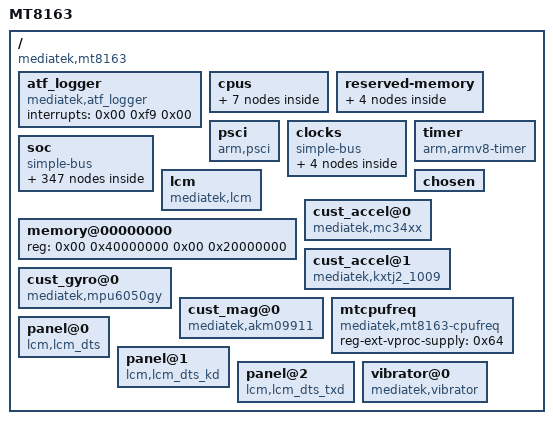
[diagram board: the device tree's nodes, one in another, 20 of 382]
/dts-v1/;

/ {
	model = "MT8163";
	compatible = "mediatek,mt8163";
	interrupt-parent = <0x01>;
	#address-cells = <0x02>;
	#size-cells = <0x02>;

	atf_logger {
		compatible = "mediatek,atf_logger";
		interrupts = <0x00 0xf9 0x00>;
	};

	cpus {
		#address-cells = <0x01>;
		#size-cells = <0x00>;

		cpu@0 {
			device_type = "cpu";
			compatible = "arm,cortex-a53";
			reg = <0x00>;
			enable-method = "mt-boot";
			cpu-idle-states = <0x02 0x02 0x03 0x03 0x03>;
			cpu-release-addr = <0x00 0x40000200>;
			clock-frequency = "M|m";
			linux,phandle = <0x07>;
			phandle = <0x07>;
		};

		cpu@1 {
			device_type = "cpu";
			compatible = "arm,cortex-a53";
			reg = <0x01>;
			enable-method = "mt-boot";
			cpu-idle-states = <0x02 0x02 0x03 0x03 0x03>;
			cpu-release-addr = <0x00 0x40000200>;
			clock-frequency = "M|m";
			linux,phandle = <0x08>;
			phandle = <0x08>;
		};

		cpu@2 {
			device_type = "cpu";
			compatible = "arm,cortex-a53";
			reg = <0x02>;
			enable-method = "mt-boot";
			cpu-idle-states = <0x02 0x02 0x03 0x03 0x03>;
			cpu-release-addr = <0x00 0x40000200>;
			clock-frequency = "M|m";
			linux,phandle = <0x09>;
			phandle = <0x09>;
		};

		cpu@3 {
			device_type = "cpu";
			compatible = "arm,cortex-a53";
			reg = <0x03>;
			enable-method = "mt-boot";
			cpu-idle-states = <0x02 0x02 0x03 0x03 0x03>;
			cpu-release-addr = <0x00 0x40000200>;
			clock-frequency = "M|m";
			linux,phandle = <0x0a>;
			phandle = <0x0a>;
		};

		idle-states {
			entry-method = "arm,psci";

			cpu-sleep-0-0 {
				compatible = "arm,idle-state";
				arm,psci-suspend-param = <0x10000>;
				entry-latency-us = <0x258>;
				exit-latency-us = <0x258>;
				min-residency-us = <0x4b0>;
				linux,phandle = <0x03>;
				phandle = <0x03>;
			};

			cluster-sleep-0 {
				compatible = "arm,idle-state";
				arm,psci-suspend-param = <0x2010000>;
				entry-latency-us = <0x320>;
				exit-latency-us = <0x3e8>;
				min-residency-us = <0x7d0>;
				linux,phandle = <0x02>;
				phandle = <0x02>;
			};
		};
	};

	reserved-memory {
		#address-cells = <0x02>;
		#size-cells = <0x02>;
		ranges;

		atf-reserved-memory@43000000 {
			compatible = "mediatek,mt8163-atf-reserved-memory";
			no-map;
			reg = <0x00 0x43000000 0x00 0x30000>;
		};

		ram_console-reserved-memory@44400000 {
			compatible = "mediatek,ram_console";
			reg = <0x00 0x44400000 0x00 0x10000>;
		};

		minirdump-reserved-memory@444f0000 {
			compatible = "mediatek,minirdump";
			reg = <0x00 0x444f0000 0x00 0x10000>;
		};

		consys-reserve-memory {
			compatible = "mediatek,consys-reserve-memory";
			no-map;
			size = <0x00 0x200000>;
			alignment = <0x00 0x200000>;
		};
	};

	psci {
		compatible = "arm,psci";
		method = "smc";
		cpu_suspend = <0x84000001>;
		cpu_off = <0x84000002>;
		cpu_on = <0x84000003>;
		affinity_info = <0x84000004>;
	};

	clocks {
		#address-cells = <0x02>;
		#size-cells = <0x02>;
		compatible = "simple-bus";
		ranges;

		clk_null {
			compatible = "fixed-clock";
			#clock-cells = <0x00>;
			clock-frequency = <0x00>;
			linux,phandle = <0x38>;
			phandle = <0x38>;
		};

		clk26m {
			compatible = "fixed-clock";
			#clock-cells = <0x00>;
			clock-frequency = <0x18cba80>;
			linux,phandle = <0x29>;
			phandle = <0x29>;
		};

		clk32k {
			compatible = "fixed-clock";
			#clock-cells = <0x00>;
			clock-frequency = <0x7d00>;
		};

		dummy26m {
			compatible = "fixed-clock";
			clock-frequency = <0x18cba80>;
			#clock-cells = <0x00>;
		};
	};

	timer {
		compatible = "arm,armv8-timer";
		interrupt-parent = <0x04>;
		interrupts = <0x01 0x0d 0xf08 0x01 0x0e 0xf08 0x01 0x0b 0xf08 0x01 0x0a 0xf08>;
		clock-frequency = <0xc65d40>;
	};

	soc {
		#address-cells = <0x02>;
		#size-cells = <0x02>;
		compatible = "simple-bus";
		ranges;

		chipid@08000000 {
			compatible = "mediatek,mt8163-chipid";
			reg = <0x00 0x8000000 0x00 0x10>;
		};

		topckgen@10000000 {
			compatible = "mediatek,mt8163-topckgen";
			reg = <0x00 0x10000000 0x00 0x1000>;
			#clock-cells = <0x01>;
			linux,phandle = <0x06>;
			phandle = <0x06>;
		};

		infracfg@10001000 {
			compatible = "mediatek,mt8163-infracfg\0syscon";
			reg = <0x00 0x10001000 0x00 0x1000>;
			#clock-cells = <0x01>;
			#reset-cells = <0x01>;
			linux,phandle = <0x05>;
			phandle = <0x05>;
		};

		syscfg_pctl_a@10005000 {
			compatible = "mediatek,mt8163-pctl-a-syscfg\0syscon";
			reg = <0x00 0x10005000 0x00 0x1000>;
			linux,phandle = <0x0b>;
			phandle = <0x0b>;
		};

		toprgu@10007000 {
			compatible = "mediatek,mt8163-rgu";
			reg = <0x00 0x10007000 0x00 0x1000>;
			interrupts = <0x00 0x80 0x02>;
			#reset-cells = <0x01>;
			linux,phandle = <0x52>;
			phandle = <0x52>;
		};

		apxgpt@10008000 {
			compatible = "mediatek,mt8163-apxgpt";
			reg = <0x00 0x10008000 0x00 0x1000>;
			interrupts = <0x00 0x98 0x08>;
			clocks = <0x05 0x06 0x05 0x46 0x06 0x60>;
			clock-names = "bus\0clk13m\0rtc_sel";
		};

		pmu {
			compatible = "arm,armv8-pmuv3";
			interrupts = <0x00 0x08 0x08 0x00 0x09 0x08 0x00 0x0a 0x08 0x00 0x0b 0x08>;
			interrupt-affinity = <0x07 0x08 0x09 0x0a>;
		};

		pinctrl@10005000 {
			compatible = "mediatek,mt8163-pinctrl";
			reg = <0x00 0x1000b000 0x00 0x1000>;
			mediatek,pctl-regmap = <0x0b>;
			pins-are-numbered;
			gpio-controller;
			#gpio-cells = <0x02>;
			interrupt-controller;
			#interrupt-cells = <0x02>;
			interrupts = <0x00 0x99 0x04 0x00 0x9a 0x04 0x00 0x9b 0x04>;
			pinctrl-names = "default";
			pinctrl-0 = <0x0c>;
			linux,phandle = <0x0d>;
			phandle = <0x0d>;

			spi1 {
				linux,phandle = <0x27>;
				phandle = <0x27>;

				pins_spi {
					pinmux = <0x3501 0x3601 0x3701 0x3801>;
					bias-disable;
				};
			};

			uart0gpiodefault {
				linux,phandle = <0x0f>;
				phandle = <0x0f>;
			};

			uart0_rx_set {
				linux,phandle = <0x10>;
				phandle = <0x10>;

				pins_cmd_dat {
					pinmux = <0x4f01>;
				};
			};

			uart0_rx_clear {
				linux,phandle = <0x11>;
				phandle = <0x11>;

				pins_cmd_dat {
					pinmux = <0x4f00>;
					slew-rate = <0x01>;
					output-high;
				};
			};

			uart0_tx_set {
				linux,phandle = <0x12>;
				phandle = <0x12>;

				pins_cmd_dat {
					pinmux = <0x5001>;
				};
			};

			uart0_tx_clear {
				linux,phandle = <0x13>;
				phandle = <0x13>;

				pins_cmd_dat {
					pinmux = <0x5000>;
					slew-rate = <0x01>;
					output-high;
				};
			};

			uart1gpiodefault {
				linux,phandle = <0x14>;
				phandle = <0x14>;
			};

			uart1_rx_set {
				linux,phandle = <0x15>;
				phandle = <0x15>;

				pins_cmd_dat {
					pinmux = <0x5101>;
				};
			};

			uart1_rx_clear {
				linux,phandle = <0x16>;
				phandle = <0x16>;

				pins_cmd_dat {
					pinmux = <0x5100>;
					slew-rate = <0x01>;
					output-high;
				};
			};

			uart1_tx_set {
				linux,phandle = <0x17>;
				phandle = <0x17>;

				pins_cmd_dat {
					pinmux = <0x5201>;
				};
			};

			uart1_tx_clear {
				linux,phandle = <0x18>;
				phandle = <0x18>;

				pins_cmd_dat {
					pinmux = <0x5200>;
					slew-rate = <0x01>;
					output-high;
				};
			};

			uart2gpiodefault {
				linux,phandle = <0x19>;
				phandle = <0x19>;
			};

			uart2_rx_set {
				linux,phandle = <0x1a>;
				phandle = <0x1a>;

				pins_cmd_dat {
					pinmux = <0xe01>;
				};
			};

			uart2_rx_clear {
				linux,phandle = <0x1b>;
				phandle = <0x1b>;

				pins_cmd_dat {
					pinmux = <0xe00>;
					slew-rate = <0x01>;
					output-high;
				};
			};

			uart2_tx_set {
				linux,phandle = <0x1c>;
				phandle = <0x1c>;

				pins_cmd_dat {
					pins = <0xf01>;
				};
			};

			uart2_tx_clear {
				linux,phandle = <0x1d>;
				phandle = <0x1d>;

				pins_cmd_dat {
					pinmux = <0xf00>;
					slew-rate = <0x01>;
					output-high;
				};
			};

			uart3gpiodefault {
				linux,phandle = <0x1e>;
				phandle = <0x1e>;
			};

			uart3_rx_set {
				linux,phandle = <0x1f>;
				phandle = <0x1f>;

				pins_cmd_dat {
					pinmux = <0x1001>;
				};
			};

			uart3_rx_clear {
				linux,phandle = <0x20>;
				phandle = <0x20>;

				pins_cmd_dat {
					pinmux = <0x1000>;
					slew-rate = <0x01>;
					output-high;
				};
			};

			uart3_tx_set {
				linux,phandle = <0x21>;
				phandle = <0x21>;

				pins_cmd_dat {
					pinmux = <0x1101>;
				};
			};

			uart3_tx_clear {
				linux,phandle = <0x22>;
				phandle = <0x22>;

				pins_cmd_dat {
					pinmux = <0x1100>;
					slew-rate = <0x01>;
					output-high;
				};
			};

			pinconf_default {
				linux,phandle = <0x0c>;
				phandle = <0x0c>;
			};

			audiodefault {
				linux,phandle = <0x2d>;
				phandle = <0x2d>;
			};

			eint4default {
				linux,phandle = <0x5b>;
				phandle = <0x5b>;
			};

			eint4 {
				linux,phandle = <0x5c>;
				phandle = <0x5c>;

				pins_cmd_dat {
					pins = <0x1a00>;
					bias-disable;
				};
			};

			audexamphigh {
				linux,phandle = <0x32>;
				phandle = <0x32>;

				pins_cmd_dat {
					pins = <0x1d00>;
					slew-rate = <0x01>;
					output-high;
				};
			};

			audexamplow {
				linux,phandle = <0x33>;
				phandle = <0x33>;

				pins_cmd_dat {
					pins = <0x1d00>;
					slew-rate = <0x01>;
					output-low;
				};
			};

			audi2s1mode0 {
				linux,phandle = <0x30>;
				phandle = <0x30>;

				pins_cmd0_dat {
					pins = <0x2e00>;
				};

				pins_cmd1_dat {
					pins = <0x2f00>;
				};

				pins_cmd2_dat {
					pins = <0x3000>;
				};
			};

			audi2s1mode1 {
				linux,phandle = <0x31>;
				phandle = <0x31>;

				pins_cmd0_dat {
					pins = <0x2e02>;
				};

				pins_cmd1_dat {
					pins = <0x2f02>;
				};

				pins_cmd2_dat {
					pins = <0x3002>;
				};
			};

			pmicclkmode0 {
				linux,phandle = <0x2e>;
				phandle = <0x2e>;

				pins_cmd0_dat {
					pins = <0x700>;
				};

				pins_cmd1_dat {
					pins = <0x800>;
				};

				pins_cmd2_dat {
					pins = <0x901>;
				};
			};

			pmicclkmode1 {
				linux,phandle = <0x2f>;
				phandle = <0x2f>;

				pins_cmd0_dat {
					pins = <0x701>;
				};

				pins_cmd1_dat {
					pins = <0x801>;
				};

				pins_cmd2_dat {
					pins = <0x901>;
				};
			};

			cam0@0 {
				linux,phandle = <0x48>;
				phandle = <0x48>;

				pins_cmd_dat {
					pins = <0x1200>;
					slew-rate = <0x01>;
					output-low;
				};
			};

			cam0@1 {
				linux,phandle = <0x49>;
				phandle = <0x49>;

				pins_cmd_dat {
					pins = <0x1200>;
					slew-rate = <0x01>;
					output-high;
				};
			};

			cam0@2 {
				linux,phandle = <0x4a>;
				phandle = <0x4a>;

				pins_cmd_dat {
					pins = <0x1400>;
					slew-rate = <0x01>;
					output-low;
				};
			};

			cam0@3 {
				linux,phandle = <0x4b>;
				phandle = <0x4b>;

				pins_cmd_dat {
					pins = <0x1400>;
					slew-rate = <0x01>;
					output-high;
				};
			};

			cam1@0 {
				linux,phandle = <0x4c>;
				phandle = <0x4c>;

				pins_cmd_dat {
					pins = <0x1300>;
					slew-rate = <0x01>;
					output-low;
				};
			};

			cam1@1 {
				linux,phandle = <0x4d>;
				phandle = <0x4d>;

				pins_cmd_dat {
					pins = <0x1300>;
					slew-rate = <0x01>;
					output-high;
				};
			};

			cam1@2 {
				linux,phandle = <0x4e>;
				phandle = <0x4e>;

				pins_cmd_dat {
					pins = <0x1500>;
					slew-rate = <0x01>;
					output-low;
				};
			};

			cam1@3 {
				linux,phandle = <0x4f>;
				phandle = <0x4f>;

				pins_cmd_dat {
					pins = <0x1500>;
					slew-rate = <0x01>;
					output-high;
				};
			};

			cam_pin_gpio {
				linux,phandle = <0x50>;
				phandle = <0x50>;

				pins_cmd_dat {
					pins = <0x7700>;
					slew-rate = <0x01>;
					output-low;
				};
			};

			cam_pin_mclk {
				linux,phandle = <0x51>;
				phandle = <0x51>;

				pins_cmd_dat {
					pins = <0x7701>;
				};
			};

			camdefault {
				linux,phandle = <0x47>;
				phandle = <0x47>;

				pins_cmd_dat {
					pins = <0x7701>;
				};
			};

			default {
				linux,phandle = <0x53>;
				phandle = <0x53>;
			};

			eint0default {
				linux,phandle = <0x5d>;
				phandle = <0x5d>;
			};

			eint@0 {
				linux,phandle = <0x5e>;
				phandle = <0x5e>;

				pins_cmd_dat {
					pins = <0x1600>;
					slew-rate = <0x00>;
					input-enable;
					bias-disable;
				};
			};

			eintoutput0 {
				linux,phandle = <0x5f>;
				phandle = <0x5f>;

				pins_cmd_dat {
					pins = <0x1600>;
					slew-rate = <0x01>;
					output-low;
				};
			};

			eintoutput1 {
				linux,phandle = <0x60>;
				phandle = <0x60>;

				pins_cmd_dat {
					pins = <0x1600>;
					slew-rate = <0x01>;
					output-high;
				};
			};

			rstoutput0 {
				linux,phandle = <0x61>;
				phandle = <0x61>;

				pins_cmd_dat {
					pins = <0x2d00>;
					slew-rate = <0x01>;
					output-low;
				};
			};

			rstoutput1 {
				linux,phandle = <0x62>;
				phandle = <0x62>;

				pins_cmd_dat {
					pins = <0x2d00>;
					slew-rate = <0x01>;
					output-high;
				};
			};

			iddig_irq_init {
				linux,phandle = <0x2b>;
				phandle = <0x2b>;

				pins_cmd_dat {
					pins = <0x2600>;
					slew-rate = <0x00>;
					bias-pull-up = <0x00>;
				};
			};

			gpslna@0 {
				linux,phandle = <0x54>;
				phandle = <0x54>;

				pins_cmd_dat {
					pinmux = <0x1900>;
					slew-rate = <0x00>;
					bias-disable;
					output-low;
				};
			};

			gpslna@1 {
				linux,phandle = <0x55>;
				phandle = <0x55>;

				pins_cmd_dat {
					pinmux = <0x1900>;
					slew-rate = <0x01>;
					output-high;
				};
			};

			gpslna@2 {
				linux,phandle = <0x56>;
				phandle = <0x56>;

				pins_cmd_dat {
					pinmux = <0x1900>;
					slew-rate = <0x01>;
					output-low;
				};
			};

			hdmi_pins_default {
				linux,phandle = <0x3d>;
				phandle = <0x3d>;

				pins_cmd_dat {
					pins = <0x1b00>;
					slew-rate = <0x01>;
					bias-pull-up;
					output-high;
				};
			};

			hdmi_pins_hpd {
				linux,phandle = <0x3e>;
				phandle = <0x3e>;

				pins_cmd_dat {
					pins = <0x8b01>;
					slew-rate = <0x00>;
					bias-pull-down;
				};
			};

			i2c0@0 {
				linux,phandle = <0x23>;
				phandle = <0x23>;

				pins1 {
					pinmux = <0x4b01 0x4c01>;
					bias-disable;
				};
			};

			i2c1@0 {
				linux,phandle = <0x24>;
				phandle = <0x24>;

				pins1 {
					pinmux = <0x3901 0x3a01>;
					bias-disable;
				};
			};

			i2c2@0 {
				linux,phandle = <0x25>;
				phandle = <0x25>;

				pins1 {
					pinmux = <0x4d01 0x4e01>;
					bias-disable;
				};
			};

			mmc0default {
				linux,phandle = <0x34>;
				phandle = <0x34>;

				pins_cmd_dat {
					pinmux = <0x8901 0x8801 0x8701 0x8601 0x8201 0x8101 0x8001 0x7f01 0x8401>;
					input-enable;
					bias-pull-up;
				};

				pins_clk {
					pinmux = <0x8501>;
					bias-pull-down;
				};

				pins_rst {
					pinmux = <0x8301>;
					bias-pull-up;
				};
			};

			mmc0@0 {
				linux,phandle = <0x35>;
				phandle = <0x35>;

				pins_cmd_dat {
					pinmux = <0x8901 0x8801 0x8701 0x8601 0x8201 0x8101 0x8001 0x7f01 0x8401>;
					input-enable;
					drive-strength = <0x06>;
					bias-pull-up = <0x65>;
				};

				pins_clk {
					pinmux = <0x8501>;
					drive-strength = <0x06>;
					bias-pull-down = <0x65>;
				};

				pins_rst {
					pinmux = <0x8301>;
					bias-pull-up;
				};
			};

			mmc1default {
				linux,phandle = <0x39>;
				phandle = <0x39>;

				pins_cmd_dat {
					pinmux = <0x7b01 0x7c01 0x7d01 0x7e01 0x7901>;
					input-enable;
					drive-strength = <0x08>;
					bias-pull-up = <0x66>;
				};

				pins_clk {
					pinmux = <0x7a01>;
					bias-pull-down;
					drive-strength = <0x08>;
				};

				pins_insert {
					pinmux = <0x3400>;
					bias-pull-up;
				};
			};

			mmc1@0 {
				linux,phandle = <0x3a>;
				phandle = <0x3a>;

				pins_cmd_dat {
					pinmux = <0x7b01 0x7c01 0x7d01 0x7e01 0x7901>;
					input-enable;
					drive-strength = <0x08>;
					bias-pull-up = <0x66>;
				};

				pins_clk {
					pinmux = <0x7a01>;
					drive-strength = <0x08>;
					bias-pull-down = <0x66>;
				};
			};
		};

		dramco@10004000 {
			compatible = "mediatek,mt8163-dramco";
			reg = <0x00 0x10004000 0x00 0x1000>;
		};

		scpsys@10006000 {
			compatible = "mediatek,mt8163-scpsys\0syscon";
			#power-domain-cells = <0x01>;
			reg = <0x00 0x10006000 0x00 0x1000>;
			interrupts = <0x00 0xa3 0x08 0x00 0xa4 0x08 0x00 0xa5 0x08 0x00 0xa6 0x08 0x00 0xa7 0x08 0x00 0xa8 0x08 0x00 0xa9 0x08 0x00 0xaa 0x08>;
			infracfg = <0x05>;
			clocks = <0x06 0x46 0x06 0x43>;
			clock-names = "mfg\0mm";
			linux,phandle = <0x2c>;
			phandle = <0x2c>;
		};

		hacc@1000a000 {
			compatible = "mediatek,hacc";
			reg = <0x00 0x1000a000 0x00 0x1000>;
			clocks = <0x05 0x05>;
			clock-names = "main";
		};

		apmixedsys@1000c000 {
			compatible = "mediatek,mt8163-apmixedsys";
			reg = <0x00 0x1000c000 0x00 0x1000>;
			#clock-cells = <0x01>;
			linux,phandle = <0x28>;
			phandle = <0x28>;
		};

		fhctl@1000cf00 {
			compatible = "mediatek,mt8163-fhctl";
			reg = <0x00 0x1000cf00 0x00 0x100>;
		};

		pwrap@0x1000d000 {
			compatible = "mediatek,mt8163-pwrap";
			reg = <0x00 0x1000d000 0x00 0x1000>;
			reg-names = "pwrap-base";
			interrupts = <0x00 0xa1 0x04>;
			clocks = <0x06 0x51 0x05 0x01>;
			clock-names = "spi\0pwrap";

			mt6323 {
				compatible = "mediatek,mt6323";

				pmicmt6323 {
					compatible = "mediatek,mt6323-pmic";
					interrupt-parent = <0x0d>;
					interrupts = <0x18 0x04>;
				};

				regulators {
					compatible = "mediatek,mt6323-regulator";

					buck_vproc {
						regulator-name = "vproc";
						regulator-min-microvolt = <0xaae60>;
						regulator-max-microvolt = <0x149970>;
						regulator-ramp-delay = <0x30d4>;
						regulator-always-on;
						regulator-boot-on;
					};

					buck_vsys {
						regulator-name = "vsys";
						regulator-min-microvolt = <0x155cc0>;
						regulator-max-microvolt = <0x2d95ec>;
						regulator-ramp-delay = <0x61a8>;
						regulator-always-on;
						regulator-boot-on;
					};

					buck_vpa {
						regulator-name = "vpa";
						regulator-min-microvolt = <0x7a120>;
						regulator-max-microvolt = <0x37b1d0>;
					};

					ldo_vtcxo {
						regulator-name = "vtcxo";
						regulator-min-microvolt = <0x2ab980>;
						regulator-max-microvolt = <0x2ab980>;
						regulator-enable-ramp-delay = <0x5a>;
						regulator-always-on;
						regulator-boot-on;
					};

					ldo_vcn28 {
						regulator-name = "vcn28";
						regulator-min-microvolt = <0x2ab980>;
						regulator-max-microvolt = <0x2ab980>;
						regulator-enable-ramp-delay = <0xb9>;
						linux,phandle = <0x58>;
						phandle = <0x58>;
					};

					ldo_vcn33_bt {
						regulator-name = "vcn33_bt";
						regulator-min-microvolt = <0x325aa0>;
						regulator-max-microvolt = <0x36ee80>;
						regulator-enable-ramp-delay = <0xb9>;
						linux,phandle = <0x59>;
						phandle = <0x59>;
					};

					ldo_vcn33_wifi {
						regulator-name = "vcn33_wifi";
						regulator-min-microvolt = <0x325aa0>;
						regulator-max-microvolt = <0x36ee80>;
						regulator-enable-ramp-delay = <0xb9>;
						linux,phandle = <0x5a>;
						phandle = <0x5a>;
					};

					ldo_va {
						regulator-name = "va";
						regulator-min-microvolt = <0x2ab980>;
						regulator-max-microvolt = <0x2ab980>;
						regulator-enable-ramp-delay = <0xd8>;
						regulator-always-on;
						regulator-boot-on;
					};

					ldo_vcama {
						regulator-name = "vcama";
						regulator-min-microvolt = <0x16e360>;
						regulator-max-microvolt = <0x2ab980>;
						regulator-enable-ramp-delay = <0xd8>;
						linux,phandle = <0x43>;
						phandle = <0x43>;
					};

					ldo_vio28 {
						regulator-name = "vio28";
						regulator-min-microvolt = <0x2ab980>;
						regulator-max-microvolt = <0x2ab980>;
						regulator-enable-ramp-delay = <0xd8>;
						regulator-always-on;
						regulator-boot-on;
					};

					ldo_vusb {
						regulator-name = "vusb";
						regulator-min-microvolt = <0x325aa0>;
						regulator-max-microvolt = <0x325aa0>;
						regulator-enable-ramp-delay = <0xd8>;
						regulator-boot-on;
						linux,phandle = <0x2a>;
						phandle = <0x2a>;
					};

					ldo_vmc {
						regulator-name = "vmc";
						regulator-min-microvolt = <0x1b7740>;
						regulator-max-microvolt = <0x325aa0>;
						regulator-enable-ramp-delay = <0x24>;
						regulator-boot-on;
						linux,phandle = <0x3c>;
						phandle = <0x3c>;
					};

					ldo_vmch {
						regulator-name = "vmch";
						regulator-min-microvolt = <0x2dc6c0>;
						regulator-max-microvolt = <0x325aa0>;
						regulator-enable-ramp-delay = <0x24>;
						regulator-boot-on;
						linux,phandle = <0x3b>;
						phandle = <0x3b>;
					};

					ldo_vemc3v3 {
						regulator-name = "vemc3v3";
						regulator-min-microvolt = <0x2dc6c0>;
						regulator-max-microvolt = <0x325aa0>;
						regulator-enable-ramp-delay = <0x24>;
						regulator-boot-on;
						linux,phandle = <0x36>;
						phandle = <0x36>;
					};

					ldo_vgp1 {
						regulator-name = "vgp1";
						regulator-min-microvolt = <0x124f80>;
						regulator-max-microvolt = <0x325aa0>;
						regulator-enable-ramp-delay = <0xd8>;
					};

					ldo_vgp2 {
						regulator-name = "vgp2";
						regulator-min-microvolt = <0x124f80>;
						regulator-max-microvolt = <0x2dc6c0>;
						regulator-enable-ramp-delay = <0xd8>;
						linux,phandle = <0x26>;
						phandle = <0x26>;
					};

					ldo_vgp3 {
						regulator-name = "vgp3";
						regulator-min-microvolt = <0x124f80>;
						regulator-max-microvolt = <0x1b7740>;
						regulator-enable-ramp-delay = <0xd8>;
						linux,phandle = <0x63>;
						phandle = <0x63>;
					};

					ldo_vcn18 {
						regulator-name = "vcn18";
						regulator-min-microvolt = <0x1b7740>;
						regulator-max-microvolt = <0x1b7740>;
						regulator-enable-ramp-delay = <0xd8>;
						linux,phandle = <0x57>;
						phandle = <0x57>;
					};

					ldo_vsim1 {
						regulator-name = "vsim1";
						regulator-min-microvolt = <0x1b7740>;
						regulator-max-microvolt = <0x2dc6c0>;
						regulator-enable-ramp-delay = <0xd8>;
					};

					ldo_vsim2 {
						regulator-name = "vsim2";
						regulator-min-microvolt = <0x1b7740>;
						regulator-max-microvolt = <0x2dc6c0>;
						regulator-enable-ramp-delay = <0xd8>;
					};

					ldo_vrtc {
						regulator-name = "vrtc";
						regulator-min-microvolt = <0x2ab980>;
						regulator-max-microvolt = <0x2ab980>;
						regulator-always-on;
						regulator-boot-on;
					};

					ldo_vcamaf {
						regulator-name = "vcamaf";
						regulator-min-microvolt = <0x124f80>;
						regulator-max-microvolt = <0x325aa0>;
						regulator-enable-ramp-delay = <0xd8>;
						linux,phandle = <0x46>;
						phandle = <0x46>;
					};

					ldo_vibr {
						regulator-name = "vibr";
						regulator-min-microvolt = <0x124f80>;
						regulator-max-microvolt = <0x325aa0>;
						regulator-enable-ramp-delay = <0x24>;
					};

					ldo_vrf18 {
						regulator-name = "vrf18";
						regulator-min-microvolt = <0x1bd8e8>;
						regulator-max-microvolt = <0x1bd8e8>;
						regulator-enable-ramp-delay = <0xbb>;
					};

					ldo_vm {
						regulator-name = "vm";
						regulator-min-microvolt = <0x124f80>;
						regulator-max-microvolt = <0x1b7740>;
						regulator-enable-ramp-delay = <0xd8>;
						regulator-always-on;
						regulator-boot-on;
					};

					ldo_vio18 {
						regulator-name = "vio18";
						regulator-min-microvolt = <0x1b7740>;
						regulator-max-microvolt = <0x1b7740>;
						regulator-enable-ramp-delay = <0xd8>;
						regulator-always-on;
						regulator-boot-on;
						linux,phandle = <0x37>;
						phandle = <0x37>;
					};

					ldo_vcamd {
						regulator-name = "vcamd";
						regulator-min-microvolt = <0x124f80>;
						regulator-max-microvolt = <0x1b7740>;
						regulator-enable-ramp-delay = <0xd8>;
						linux,phandle = <0x44>;
						phandle = <0x44>;
					};

					ldo_vcamio {
						regulator-name = "vcamio";
						regulator-min-microvolt = <0x1b7740>;
						regulator-max-microvolt = <0x1b7740>;
						regulator-enable-ramp-delay = <0xd8>;
						linux,phandle = <0x45>;
						phandle = <0x45>;
					};
				};
			};
		};

		devapc_ao@1000e000 {
			compatible = "mediatek,mt8163-devapc_ao";
			reg = <0x00 0x1000e000 0x00 0x1000>;
		};

		ddrphy@1000f000 {
			compatible = "mediatek,mt8163-ddrphy\0mediatek,ddrphy";
			reg = <0x00 0x1000f000 0x00 0x1000>;
			clocks = <0x05 0x36>;
			clock-names = "dramc_f26m";
		};

		keypad@10010000 {
			compatible = "mediatek,mt8163-keypad";
			reg = <0x00 0x10010000 0x00 0x1000>;
			interrupts = <0x00 0xa2 0x02>;
			mediatek,kpd-key-debounce = <0x400>;
			mediatek,kpd-sw-pwrkey = <0x74>;
			mediatek,kpd-hw-pwrkey = <0x08>;
			mediatek,kpd-sw-rstkey = <0x72>;
			mediatek,kpd-hw-rstkey = <0x11>;
			mediatek,kpd-use-extend-type = <0x00>;
			mediatek,kpd-hw-map-num = <0x48>;
			mediatek,kpd-hw-init-map = <0x73 0x00 0x00 0x00 0x00 0x00 0x00 0x00 0x00 0x00 0x00 0x00 0x00 0x00 0x00 0x00 0x00 0x00 0x00 0x00 0x00 0x00 0x00 0x00 0x00 0x00 0x00 0x00 0x00 0x00 0x00 0x00 0x00 0x00 0x00 0x00 0x00 0x00 0x00 0x00 0x00 0x00 0x00 0x00 0x00 0x00 0x00 0x00 0x00 0x00 0x00 0x00 0x00 0x00 0x00 0x00 0x00 0x00 0x00 0x00 0x00 0x00 0x00 0x00 0x00 0x00 0x00 0x00 0x00 0x00 0x00 0x00>;
			mediatek,kpd-pwrkey-eint-gpio = <0x00>;
			mediatek,kpd-pwkey-gpio-din = <0x00>;
			mediatek,kpd-hw-dl-key0 = <0x00>;
			mediatek,kpd-hw-dl-key1 = <0x11>;
			mediatek,kpd-hw-dl-key2 = <0x08>;
			mediatek,kpd-hw-recovery-key = <0x11>;
			mediatek,kpd-hw-factory-key = <0x00>;
		};

		md32@10020000 {
			compatible = "mediatek,mt8163-md32";
			reg = <0x00 0x10020000 0x00 0x38000 0x00 0x10058000 0x00 0x400 0x00 0x10059000 0x00 0x400>;
			interrupts = <0x00 0xae 0x04>;
			clocks = <0x05 0x04>;
			clock-names = "sys";
			status = "okay";
		};

		mcucfg@10200000 {
			compatible = "mediatek,mt8173-mcucfg\0syscon";
			reg = <0x00 0x10200000 0x00 0x1000>;
		};

		cpuxgpt@10200000 {
			compatible = "mediatek,mt8163-cpuxgpt";
			interrupts = <0x00 0x40 0x04 0x00 0x41 0x04 0x00 0x42 0x04 0x00 0x43 0x04>;
		};

		lastpc@10200000 {
			compatible = "mediatek,mt8163-mcucfg";
			reg = <0x00 0x10200000 0x00 0x200>;
		};

		intpol-controller@10200620 {
			compatible = "mediatek,mt8163-sysirq\0mediatek,mt6577-sysirq";
			interrupt-controller;
			#interrupt-cells = <0x03>;
			interrupt-parent = <0x04>;
			reg = <0x00 0x10200620 0x00 0x20>;
			linux,phandle = <0x01>;
			phandle = <0x01>;
		};

		emi@10203000 {
			compatible = "mediatek,mt8163-emi\0mediatek,emi";
			reg = <0x00 0x10203000 0x00 0x1000>;
			interrupts = <0x00 0x85 0x04>;
		};

		sys_cirq@10204000 {
			compatible = "mediatek,mt8163-sys_cirq\0mediatek,mt6735-sys_cirq";
			reg = <0x00 0x10204000 0x00 0x1000>;
			interrupts = <0x00 0xf0 0x08>;
			mediatek,cirq_num = <0xa9>;
			mediatek,spi_start_offset = <0x48>;
		};

		m4u@10205000 {
			cell-index = <0x00>;
			compatible = "mediatek,mt8163-m4u";
			reg = <0x00 0x10205000 0x00 0x1000>;
			interrupts = <0x00 0x93 0x08>;
		};

		devapc@10207000 {
			compatible = "mediatek,mt8163-devapc";
			reg = <0x00 0x10207000 0x00 0x1000>;
			interrupts = <0x00 0x85 0x08>;
			clocks = <0x05 0x2b>;
			clock-names = "main";
		};

		systracker@10208000 {
			compatible = "mediatek,bus_dbg-v1";
			reg = <0x00 0x10208000 0x00 0x1000>;
			interrupts = <0x00 0x84 0x08>;
		};

		dramc_nao@1020e000 {
			compatible = "mediatek,mt8163-dramc_nao\0mediatek,dramc_nao";
			reg = <0x00 0x1020e000 0x00 0x1000>;
		};

		gcpu@10210000 {
			compatible = "mediatek,mt8163-gcpu";
			reg = <0x00 0x10210000 0x00 0x1000>;
			clocks = <0x05 0x20>;
			clock-names = "main";
		};

		gce@10212000 {
			compatible = "mediatek,mt8163-gce";
			reg = <0x00 0x10212000 0x00 0x1000>;
			interrupts = <0x00 0x8f 0x08 0x00 0x90 0x08>;
			disp_mutex_reg = <0x14015000 0x1000>;
			g3d_config_base = <0x13000000 0x00 0xffff0000>;
			mmsys_config_base = <0x14000000 0x01 0xffff0000>;
			disp_dither_base = <0x14010000 0x02 0xffff0000>;
			mm_na_base = <0x14020000 0x03 0xffff0000>;
			imgsys_base = <0x15000000 0x04 0xffff0000>;
			vdec_gcon_base = <0x16000000 0x05 0xffff0000>;
			venc_gcon_base = <0x17000000 0x06 0xffff0000>;
			conn_peri_base = <0x18000000 0x07 0xffff0000>;
			topckgen_base = <0x10000000 0x08 0xffff0000>;
			kp_base = <0x10010000 0x09 0xffff0000>;
			scp_sram_base = <0x10020000 0x0a 0xffff0000>;
			infra_na3_base = <0x10030000 0x0b 0xffff0000>;
			infra_na4_base = <0x10040000 0x0c 0xffff0000>;
			scp_base = <0x10050000 0x0d 0xffff0000>;
			mcucfg_base = <0x10200000 0x0e 0xffff0000>;
			gcpu_base = <0x10210000 0x0f 0xffff0000>;
			usb0_base = <0x11200000 0x10 0xffff0000>;
			usb_sif_base = <0x11210000 0x11 0xffff0000>;
			audio_base = <0x11220000 0x12 0xffff0000>;
			msdc0_base = <0x11230000 0x13 0xffff0000>;
			msdc1_base = <0x11240000 0x14 0xffff0000>;
			msdc2_base = <0x11250000 0x15 0xffff0000>;
			msdc3_base = <0x11260000 0x16 0xffff0000>;
			mdp_rdma0_sof = <0x00>;
			mdp_rsz0_sof = <0x01>;
			mdp_rsz1_sof = <0x02>;
			mdp_tdshp_sof = <0x03>;
			mdp_wdma_sof = <0x04>;
			mdp_wrot_sof = <0x05>;
			disp_ovl0_sof = <0x06>;
			disp_ovl1_sof = <0x07>;
			disp_rdma0_sof = <0x08>;
			disp_rdma1_sof = <0x09>;
			disp_wdma0_sof = <0x0a>;
			disp_color_sof = <0x0b>;
			disp_ccorr_sof = <0x0c>;
			disp_aal_sof = <0x0d>;
			disp_gamma_sof = <0x0e>;
			disp_dither_sof = <0x0f>;
			disp_ufoe_sof = <0x10>;
			disp_pwm0_sof = <0x11>;
			disp_wdma1_sof = <0x12>;
			ufod_rdma0_l0_sof = <0x13>;
			ufod_rdma0_l1_sof = <0x14>;
			ufod_rdma0_l2_sof = <0x15>;
			ufod_rdma0_l3_sof = <0x16>;
			ufod_rdma1_l0_sof = <0x17>;
			ufod_rdma1_l1_sof = <0x18>;
			ufod_rdma1_l2_sof = <0x19>;
			ufod_rdma1_l3_sof = <0x1a>;
			disp_dsc_sof = <0x1b>;
			mdp_rdma0_frame_done = <0x1c>;
			mdp_rsz0_frame_done = <0x1d>;
			mdp_rsz1_frame_done = <0x1e>;
			mdp_tdshp_frame_done = <0x1f>;
			mdp_wdma_frame_done = <0x20>;
			mdp_wrot_write_frame_done = <0x21>;
			mdp_wrot_read_frame_done = <0x22>;
			disp_ovl0_frame_done = <0x23>;
			disp_ovl1_frame_done = <0x24>;
			disp_rdma0_frame_done = <0x25>;
			disp_rdma1_frame_done = <0x26>;
			disp_wdma0_frame_done = <0x27>;
			disp_color_frame_done = <0x28>;
			disp_ccorr_frame_done = <0x29>;
			disp_aal_frame_done = <0x2a>;
			disp_gamma_frame_done = <0x2b>;
			disp_dither_frame_done = <0x2c>;
			disp_ufoe_frame_done = <0x2d>;
			disp_dpi0_frame_done = <0x2e>;
			disp_wdma1_frame_done = <0x2f>;
			ufod_rdma0_l0_frame_done = <0x30>;
			ufod_rdma0_l1_frame_done = <0x31>;
			ufod_rdma0_l2_frame_done = <0x32>;
			ufod_rdma0_l3_frame_done = <0x33>;
			ufod_rdma1_l0_frame_done = <0x34>;
			ufod_rdma1_l1_frame_done = <0x35>;
			ufod_rdma1_l2_frame_done = <0x36>;
			ufod_rdma1_l3_frame_done = <0x37>;
			disp_dpi1_frame_done = <0x38>;
			disp_dsc_frame_done = <0x39>;
			stream_done_0 = <0x3a>;
			stream_done_1 = <0x3b>;
			stream_done_2 = <0x3c>;
			stream_done_3 = <0x3d>;
			stream_done_4 = <0x3e>;
			stream_done_5 = <0x3f>;
			stream_done_6 = <0x40>;
			stream_done_7 = <0x41>;
			stream_done_8 = <0x42>;
			stream_done_9 = <0x43>;
			buf_underrun_event_0 = <0x44>;
			buf_underrun_event_1 = <0x45>;
			dsi0_te_event = <0x46>;
			isp_frame_done_b = <0x82>;
			isp_frame_done_a = <0x83>;
			isp_frame_done_p2_0 = <0x83>;
			isp_frame_done_p2_1 = <0x82>;
			seninf_1_fifo_full = <0x87>;
			venc_done = <0x101>;
			jpgenc_done = <0x102>;
			jpgdec_done = <0x103>;
			venc_mb_done = <0x104>;
			venc_128byte_cnt_done = <0x105>;
			clocks = <0x05 0x09 0x0e 0x00 0x0e 0x01 0x0e 0x02 0x0e 0x03 0x0e 0x04 0x0e 0x05 0x0e 0x06 0x0e 0x08 0x0e 0x07>;
			clock-names = "MT_CG_INFRA_GCE\0MT_CG_DISP0_SMI_COMMON\0MT_CG_DISP0_SMI_LARB0\0MT_CG_DISP0_CAM_MDP\0MT_CG_DISP0_MDP_RDMA\0MT_CG_DISP0_MDP_RSZ0\0MT_CG_DISP0_MDP_RSZ1\0MT_CG_DISP0_MDP_TDSHP\0MT_CG_DISP0_MDP_WROT\0MT_CG_DISP0_MDP_WDMA";
		};

		perisys_iommu@10214000 {
			cell-index = <0x01>;
			compatible = "mediatek,mt8163-perisys_iommu";
			reg = <0x00 0x10214000 0x00 0x1000>;
			interrupts = <0x00 0x91 0x08>;
		};

		interrupt-controller@10221000 {
			compatible = "arm,gic-400";
			interrupt-controller;
			#interrupt-cells = <0x03>;
			interrupt-parent = <0x04>;
			reg = <0x00 0x10221000 0x00 0x1000 0x00 0x10222000 0x00 0x1000 0x00 0x10224000 0x00 0x2000 0x00 0x10226000 0x00 0x2000>;
			interrupts = <0x01 0x09 0xf04>;
			linux,phandle = <0x04>;
			phandle = <0x04>;
		};

		btif_tx@11000700 {
			compatible = "mediatek,btif_tx";
			reg = <0x00 0x11000700 0x00 0x80>;
			interrupts = <0x00 0x6e 0x08>;
		};

		btif_rx@11000780 {
			compatible = "mediatek,btif_rx";
			reg = <0x00 0x11000780 0x00 0x80>;
			interrupts = <0x00 0x6f 0x08>;
		};

		auxadc@11001000 {
			compatible = "mediatek,mt8163-auxadc\0mediatek,mt6735-auxadc";
			reg = <0x00 0x11001000 0x00 0x1000>;
			interrupts = <0x00 0x4c 0x02>;
			clocks = <0x05 0x21>;
			clock-names = "auxadc-main";
		};

		uart0@11002000 {
			cell-index = <0x00>;
			compatible = "mediatek,mt8163-uart";
			reg = <0x00 0x11002000 0x00 0x1000 0x00 0x11000300 0x00 0x1000 0x00 0x11000380 0x00 0x80>;
			interrupts = <0x00 0x5b 0x08 0x00 0x66 0x08 0x00 0x67 0x08>;
			clock-frequency = <0x18cba80>;
			clock-div = <0x01>;
			clocks = <0x05 0x13 0x05 0x29>;
			clock-names = "uart0-main\0uart-apdma";
			pinctrl-names = "uart0_gpio_default\0uart0_rx_set\0uart0_rx_clear\0uart0_tx_set\0uart0_tx_clear";
			pinctrl-0 = <0x0f>;
			pinctrl-1 = <0x10>;
			pinctrl-2 = <0x11>;
			pinctrl-3 = <0x12>;
			pinctrl-4 = <0x13>;
			rx_gpios = <0x0d 0x4f 0x00>;
			tx_gpios = <0x0d 0x50 0x00>;
			status = "okay";
		};

		uart1@11003000 {
			cell-index = <0x01>;
			compatible = "mediatek,mt8163-uart";
			reg = <0x00 0x11003000 0x00 0x1000 0x00 0x11000400 0x00 0x80 0x00 0x11000480 0x00 0x80>;
			interrupts = <0x00 0x5c 0x08 0x00 0x68 0x08 0x00 0x69 0x08>;
			clock-frequency = <0x18cba80>;
			clock-div = <0x01>;
			clocks = <0x05 0x14>;
			clock-names = "uart1-main";
			pinctrl-names = "uart1_gpio_default\0uart1_rx_set\0uart1_rx_clear\0uart1_tx_set\0uart1_tx_clear";
			pinctrl-0 = <0x14>;
			pinctrl-1 = <0x15>;
			pinctrl-2 = <0x16>;
			pinctrl-3 = <0x17>;
			pinctrl-4 = <0x18>;
			rx_gpios = <0x0d 0x51 0x00>;
			tx_gpios = <0x0d 0x52 0x00>;
			status = "disable";
		};

		uart2@11004000 {
			cell-index = <0x02>;
			compatible = "mediatek,mt8163-uart";
			reg = <0x00 0x11004000 0x00 0x1000 0x00 0x11000500 0x00 0x80 0x00 0x11000580 0x00 0x80>;
			interrupts = <0x00 0x5d 0x08 0x00 0x6a 0x08 0x00 0x6b 0x08>;
			clock-frequency = <0x18cba80>;
			clock-div = <0x01>;
			clocks = <0x05 0x15>;
			clock-names = "uart2-main";
			pinctrl-names = "uart2_gpio_default\0uart2_rx_set\0uart2_rx_clear\0uart2_tx_set\0uart2_tx_clear";
			pinctrl-0 = <0x19>;
			pinctrl-1 = <0x1a>;
			pinctrl-2 = <0x1b>;
			pinctrl-3 = <0x1c>;
			pinctrl-4 = <0x1d>;
			rx_gpios = <0x0d 0x0e 0x00>;
			tx_gpios = <0x0d 0x0f 0x00>;
			status = "disable";
		};

		uart3@11005000 {
			cell-index = <0x03>;
			compatible = "mediatek,mt8163-uart";
			reg = <0x00 0x11005000 0x00 0x1000 0x00 0x11000600 0x00 0x80 0x00 0x11000680 0x00 0x80>;
			interrupts = <0x00 0x5e 0x08 0x00 0x6c 0x08 0x00 0x6d 0x08>;
			clock-frequency = <0x18cba80>;
			clock-div = <0x01>;
			clocks = <0x05 0x16>;
			clock-names = "uart3-main";
			pinctrl-names = "uart3_gpio_default\0uart3_rx_set\0uart3_rx_clear\0uart3_tx_set\0uart3_tx_clear";
			pinctrl-0 = <0x1e>;
			pinctrl-1 = <0x1f>;
			pinctrl-2 = <0x20>;
			pinctrl-3 = <0x21>;
			pinctrl-4 = <0x22>;
			rx_gpios = <0x0d 0x10 0x00>;
			tx_gpios = <0x0d 0x11 0x00>;
			status = "disable";
		};

		pwm@11006000 {
			compatible = "mediatek,mt8163-pwm";
			reg = <0x00 0x11006000 0x00 0x1000>;
			interrupts = <0x00 0x4d 0x08>;
			clocks = <0x05 0x12 0x05 0x0f 0x05 0x10 0x05 0x11>;
			clock-names = "PWM-main\0PWM1-main\0PWM2-main\0PWM3-main";
		};

		i2c@11007000 {
			compatible = "mediatek,mt8173-i2c";
			reg = <0x00 0x11007000 0x00 0x70 0x00 0x11000180 0x00 0x80>;
			interrupts = <0x00 0x54 0x08>;
			clock-div = <0x0a>;
			clocks = <0x05 0x0b 0x05 0x29>;
			clock-names = "main\0dma";
			#address-cells = <0x01>;
			#size-cells = <0x00>;
			status = "okay";
			pinctrl-names = "default";
			pinctrl-0 = <0x23>;
			md32,semaphore = <0x02>;

			camera_main_af@18 {
				compatible = "mediatek,camera_main_af";
				reg = <0x18>;
			};

			lp8557_led@2c {
				compatible = "ti,lp8557-led";
				reg = <0x2c>;
			};

			kd_camera_hw2@3d {
				compatible = "mediatek,camera_sub";
				reg = <0x3d>;
			};

			kd_camera_hw1@37 {
				compatible = "mediatek,camera_main";
				reg = <0x37>;
			};
		};

		i2c@11008000 {
			compatible = "mediatek,mt8173-i2c";
			reg = <0x00 0x11008000 0x00 0x70 0x00 0x11000200 0x00 0x80>;
			interrupts = <0x00 0x55 0x08>;
			clock-div = <0x0a>;
			clocks = <0x05 0x0c 0x05 0x29>;
			clock-names = "main\0dma";
			#address-cells = <0x01>;
			#size-cells = <0x00>;
			status = "okay";
			clock-frequency = <0x16e360>;
			pinctrl-names = "default";
			pinctrl-0 = <0x24>;

			sym827@60 {
				compatible = "silergy,sym827-regulator";
				reg = <0x60>;
				regulator-name = "vproc";
				regulator-min-microvolt = <0x927c0>;
				regulator-max-microvolt = <0x152bec>;
				regulator-enable-ramp-delay = <0x190>;
				regulator-ramp-delay = <0x208d>;
				regulator-always-on;
				vsel-gpio = <0x0d 0x22 0x00>;
				linux,phandle = <0x64>;
				phandle = <0x64>;
			};
		};

		i2c@11009000 {
			compatible = "mediatek,mt8173-i2c";
			reg = <0x00 0x11009000 0x00 0x70 0x00 0x11000280 0x00 0x80>;
			interrupts = <0x00 0x56 0x08>;
			clock-div = <0x0a>;
			clocks = <0x05 0x0d 0x05 0x29>;
			clock-names = "main\0dma";
			#address-cells = <0x01>;
			#size-cells = <0x00>;
			status = "okay";
			clock-frequency = <0x493e0>;
			pinctrl-names = "default";
			pinctrl-0 = <0x25>;
			md32,semaphore = <0x07>;

			cap_touch@5d {
				compatible = "mediatek,goodix_touch";
				vtouch-supply = <0x26>;
				reg = <0x5d>;
				interrupt-parent = <0x0d>;
				interrupts = <0x00 0x02>;
				int-gpio = <0x0d 0x16 0x00>;
				rst-gpio = <0x0d 0x2d 0x00>;
			};

			cap_touch1@40 {
				compatible = "mediatek,cap_touch";
				vtouch-supply = <0x26>;
				reg = <0x40>;
				interrupt-parent = <0x0d>;
				interrupts = <0x00 0x02>;
				int-gpio = <0x0d 0x16 0x00>;
				rst-gpio = <0x0d 0x2d 0x00>;
			};

			msensor@0c {
				compatible = "mediatek,msensor";
				reg = <0x0c>;
				rst-gpio = <0x0d 0x34 0x00>;
			};

			gsensor@68 {
				compatible = "mediatek,gsensor";
				reg = <0x68>;
			};

			gyro@69 {
				compatible = "mediatek,gyro";
				reg = <0x69>;
			};

			sm5414@49 {
				compatible = "sm,sm5414";
				reg = <0x49>;
				interrupt-parent = <0x0d>;
				interrupts = <0x0b 0x02>;
				gpio_pwr_chgen = <0x0d 0x18 0x00>;
				gpio_chrg_nint = <0x0d 0x2b 0x00>;
				gpio_chrg_shdn = <0x0d 0x17 0x00>;
			};
		};

		spi@1100a000 {
			compatible = "mediatek,mt8163-spi";
			#address-cells = <0x01>;
			#size-cells = <0x00>;
			reg = <0x00 0x1100a000 0x00 0x1000>;
			interrupts = <0x00 0x76 0x08>;
			clocks = <0x06 0x29 0x06 0x49 0x05 0x1b>;
			clock-names = "parent-clk\0sel-clk\0spi-clk";
			pinctrl-names = "default";
			pinctrl-0 = <0x27>;
			status = "disabled";
		};

		thermal@1100b000 {
			compatible = "mediatek,mt8163-thermal";
			reg = <0x00 0x1100b000 0x00 0x1000>;
			interrupts = <0x00 0x4e 0x08>;
			clocks = <0x05 0x0a 0x05 0x21>;
			clock-names = "therm\0auxadc";
			apmixedsys = <0x28>;
		};

		ptp_od@1100b000 {
			compatible = "mediatek,mt8163-ptp_od";
			reg = <0x00 0x1100b000 0x00 0x1000>;
			interrupts = <0x00 0x7d 0x08>;
			clocks = <0x05 0x0a>;
			clock-names = "ptp_infra_therm";
		};

		btif@1100c000 {
			compatible = "mediatek,btif";
			reg = <0x00 0x1100c000 0x00 0x1000>;
			interrupts = <0x00 0x70 0x08>;
			clocks = <0x05 0x1a 0x05 0x29>;
			clock-names = "btifc\0apdmac";
		};

		nfi@1100d000 {
			compatible = "mediatek,mt8163-nfi";
			reg = <0x00 0x1100d000 0x00 0x1000>;
			interrupts = <0x00 0x60 0x08>;
			clocks = <0x05 0x32 0x05 0x28 0x05 0x27 0x06 0x5d 0x29 0x06 0x26 0x06 0x21 0x05 0x45 0x06 0x40 0x05 0x3c 0x05 0x18 0x05 0x19 0x05 0x33>;
			clock-names = "nfi_hclk\0nfiecc_bclk\0nfi_bclk\0onfi_sel\0onfi_clk26m\0onfi_mode5\0onfi_mode4\0nfi_bclk_sel\0nfi_ahb_clk\0nfi_1xpad_clk\0nfiecc_pclk\0nfi_pclk\0onfi_pad_clk";
		};

		nfiecc@1100e000 {
			compatible = "mediatek,mt8163-nfiecc";
			reg = <0x00 0x1100e000 0x00 0x1000>;
			interrupts = <0x00 0x5f 0x08>;
		};

		usb@11200000 {
			compatible = "mediatek,mt8163-usb20";
			reg = <0x00 0x11200000 0x00 0x10000 0x00 0x11210000 0x00 0x10000>;
			interrupts = <0x00 0x48 0x08>;
			mode = <0x02>;
			multipoint = <0x01>;
			dyn_fifo = <0x01>;
			soft_con = <0x01>;
			dma = <0x01>;
			num_eps = <0x10>;
			dma_channels = <0x08>;
			clocks = <0x28 0x02 0x05 0x17 0x05 0x07>;
			clock-names = "usbpll\0usbmcu\0usb";
			vusb-supply = <0x2a>;
			pinctrl-names = "iddig_irq_init";
			pinctrl-0 = <0x2b>;
			iddig_gpio = <0x0d 0x26 0x00>;
			status = "okay";
		};

		audiosys@11220000 {
			compatible = "mediatek,mt8163-audiosys\0syscon";
			reg = <0x00 0x11220000 0x00 0x1000>;
			#clock-cells = <0x01>;
		};

		mt_soc_dl1_pcm@11220000 {
			compatible = "mediatek,mt8163-soc-pcm-dl1";
			reg = <0x00 0x11220000 0x00 0x1000 0x00 0x11221000 0x00 0x9000>;
			interrupts = <0x00 0x8e 0x08>;
			clocks = <0x05 0x30 0x06 0x4f 0x06 0x50 0x06 0x57 0x06 0x58 0x06 0x0a 0x06 0x0b 0x29>;
			clock-names = "aud_infra_clk\0top_mux_audio\0top_mux_audio_intbus\0aud_mux1_clk\0aud_mux2_clk\0top_apll1_clk\0top_apll2_clk\0top_clk26m_clk";
			power-domains = <0x2c 0x05>;
			pinctrl-names = "default\0audpmicclk-mode0\0audpmicclk-mode1\0audi2s1-mode0\0audi2s1-mode1\0extamp-pullhigh\0extamp-pulllow";
			pinctrl-0 = <0x2d>;
			pinctrl-1 = <0x2e>;
			pinctrl-2 = <0x2f>;
			pinctrl-3 = <0x30>;
			pinctrl-4 = <0x31>;
			pinctrl-5 = <0x32>;
			pinctrl-6 = <0x33>;
			status = "okay";
		};

		mt_soc_dl2_pcm@11220000 {
			compatible = "mediatek,mt8163-soc-pcm-dl2";
		};

		mt_soc_ul1_pcm@11220000 {
			compatible = "mediatek,mt8163-soc-pcm-capture";
		};

		mt_soc_voice_md1@11220000 {
			compatible = "mediatek,mt8163-soc-pcm-voice-md1";
		};

		mt_soc_hdmi_pcm@11220000 {
			compatible = "mediatek,mt8163-soc-pcm-hdmi";
		};

		mt_soc_uldlloopback@11220000 {
			compatible = "mediatek,mt8163-soc-pcm-uldlloopback";
		};

		mt_soc_i2s0_pcm@11220000 {
			compatible = "mediatek,mt8163-soc-pcm-dl1-i2s0";
		};

		mt_soc_mrgrx_pcm@11220000 {
			compatible = "mediatek,mt8163-soc-pcm-mrgrx";
		};

		mt_soc_mrgrx_awb_pcm@11220000 {
			compatible = "mediatek,mt8163-soc-pcm-mrgrx-awb";
		};

		mt_soc_fm_i2s_pcm@11220000 {
			compatible = "mediatek,mt8163-soc-pcm-fm-i2s";
		};

		mt_soc_fm_i2s_awb_pcm@11220000 {
			compatible = "mediatek,mt8163-soc-pcm-fm-i2s-awb";
		};

		mt_soc_i2s0dl1_pcm@11220000 {
			compatible = "mediatek,mt8163-soc-pcm-dl1-i2s0Dl1";
		};

		mt_soc_dl1_awb_pcm@11220000 {
			compatible = "mediatek,mt8163-soc-pcm-dl1-awb";
		};

		mt_soc_voice_md1_bt@11220000 {
			compatible = "mediatek,mt8163-soc-pcm-voice-md1-bt";
		};

		mt_soc_voip_bt_out@11220000 {
			compatible = "mediatek,mt8163-soc-pcm-dl1-bt";
		};

		mt_soc_voip_bt_in@11220000 {
			compatible = "mediatek,mt8163-soc-pcm-bt-dai";
		};

		mt_soc_tdmrx_pcm@11220000 {
			compatible = "mediatek,mt8163-soc-tdm-capture";
		};

		mt_soc_fm_mrgtx_pcm@11220000 {
			compatible = "mediatek,mt8163-soc-pcm-fmtx";
		};

		mt_soc_ul2_pcm@11220000 {
			compatible = "mediatek,mt8163-soc-pcm-capture2";
		};

		mt_soc_i2s0_awb_pcm@11220000 {
			compatible = "mediatek,mt8163-soc-pcm-i2s0-awb";
		};

		mt_soc_voice_md2@11220000 {
			compatible = "mediatek,mt8163-soc-pcm-voice-md2";
		};

		mt_soc_routing_pcm@11220000 {
			compatible = "mediatek,mt8163-soc-pcm-routing";
		};

		mt_soc_voice_md2_bt@11220000 {
			compatible = "mediatek,mt8163-soc-pcm-voice-md2-bt";
		};

		mt_soc_hp_impedance@11220000 {
			compatible = "mediatek,mt8163-soc-pcm-hp-impedance";
		};

		mt_soc_codec_name@11220000 {
			compatible = "mediatek,mt8163-soc-codec-63xx";
		};

		mt_soc_dummy_pcm@11220000 {
			compatible = "mediatek,mt8163-soc-pcm-dummy";
		};

		mt_soc_codec_dummy_name@11220000 {
			compatible = "mediatek,mt8163-soc-codec-dummy";
		};

		mt_soc_routing_dai_name@11220000 {
			compatible = "mediatek,mt8163-soc-dai-routing";
		};

		mt_soc_dai_name@11220000 {
			compatible = "mediatek,mt8163-soc-dai-stub";
		};

		mfg@13000000 {
			compatible = "mediatek,mt8163-mfg\0mediatek,midgard-mfg";
			reg = <0x00 0x13000000 0x00 0x1000>;
			clocks = <0x06 0x46 0x06 0x18>;
			clock-names = "topck\0pll";
		};

		gpu@13040000 {
			compatible = "arm,malit720\0arm,mali-t72x\0arm,malit7xx\0arm,mali-midgard";
			reg = <0x00 0x13040000 0x00 0x4000>;
			interrupts = <0x00 0xe3 0x08 0x00 0xe2 0x08 0x00 0xe1 0x08>;
			interrupt-names = "JOB\0MMU\0GPU";
			clock-frequency = <0x1efe9200>;
			power-domains = <0x2c 0x07>;
		};

		mmc@11230000 {
			compatible = "mediatek,mt8163-mmc";
			reg = <0x00 0x11230000 0x00 0x1000>;
			interrupts = <0x00 0x4f 0x08>;
			clocks = <0x05 0x1f 0x05 0x1c>;
			clock-names = "source\0hclk";
			status = "okay";
			pinctrl-names = "default\0state_uhs";
			pinctrl-0 = <0x34>;
			pinctrl-1 = <0x35>;
			bus-width = <0x08>;
			latch-ck = <0x01>;
			max-frequency = <0xbebc200>;
			cap-mmc-highspeed;
			mmc-hs200-1_8v;
			cap-mmc-hw-reset;
			vmmc-supply = <0x36>;
			vqmmc-supply = <0x37>;
			non-removable;
		};

		mmc@11240000 {
			compatible = "mediatek,mt8163-mmc";
			reg = <0x00 0x11240000 0x00 0x1000>;
			interrupts = <0x00 0x50 0x08>;
			clocks = <0x05 0x1d 0x38>;
			clock-names = "source\0hclk";
			status = "okay";
			pinctrl-names = "default\0state_uhs";
			pinctrl-0 = <0x39>;
			pinctrl-1 = <0x3a>;
			bus-width = <0x04>;
			latch-ck = <0x01>;
			max-frequency = <0xbebc200>;
			cap-sd-highspeed;
			sd-uhs-sdr50;
			sd-uhs-sdr104;
			cd-gpios = <0x0d 0x34 0x00>;
			vmmc-supply = <0x3b>;
			vqmmc-supply = <0x3c>;
		};

		usb@11270000 {
			compatible = "mediatek,mt8163-usb11";
			cell-index = <0x01>;
			reg = <0x00 0x11270000 0x00 0x10000 0x00 0x11210000 0x00 0x10000>;
			interrupts = <0x00 0x49 0x08>;
			mode = <0x02>;
			multipoint = <0x01>;
			dyn_fifo = <0x01>;
			soft_con = <0x01>;
			dma = <0x01>;
			num_eps = <0x08>;
			dma_channels = <0x04>;
			clocks = <0x28 0x02 0x05 0x17 0x05 0x08>;
			clock-names = "usbpll\0usbmcu\0icusb";
			status = "disabled";
		};

		mmsys@14000000 {
			compatible = "mediatek,mt8163-mmsys\0syscon";
			reg = <0x00 0x14000000 0x00 0x1000>;
			#clock-cells = <0x01>;
			linux,phandle = <0x0e>;
			phandle = <0x0e>;
		};

		mdp_rdma@14001000 {
			compatible = "mediatek,mt8163-mdp_rdma";
			reg = <0x00 0x14001000 0x00 0x1000>;
			interrupts = <0x00 0xb2 0x08>;
		};

		mdp_rsz0@14002000 {
			compatible = "mediatek,mt8163-mdp_rsz0";
			reg = <0x00 0x14002000 0x00 0x1000>;
			interrupts = <0x00 0xb3 0x08>;
		};

		mdp_rsz1@14003000 {
			compatible = "mediatek,mt8163-mdp_rsz1";
			reg = <0x00 0x14003000 0x00 0x1000>;
			interrupts = <0x00 0xb4 0x08>;
		};

		mdp_wdma@14004000 {
			compatible = "mediatek,mt8163-mdp_wdma";
			reg = <0x00 0x14004000 0x00 0x1000>;
			interrupts = <0x00 0xb6 0x08>;
		};

		mdp_wrot@14005000 {
			compatible = "mediatek,mt8163-mdp_wrot";
			reg = <0x00 0x14005000 0x00 0x1000>;
			interrupts = <0x00 0xb7 0x08>;
		};

		mdp_tdshp@14006000 {
			compatible = "mediatek,mt8163-mdp_tdshp0";
			reg = <0x00 0x14006000 0x00 0x1000>;
			interrupts = <0x00 0xb5 0x08>;
		};

		mt8163-dispsys {
			compatible = "mediatek,mt8163-dispsys";
		};

		disp_ovl0@14007000 {
			compatible = "mediatek,mt8163-disp_ovl0";
			reg = <0x00 0x14007000 0x00 0x1000>;
			interrupts = <0x00 0xb8 0x08>;
		};

		disp_ovl1@14008000 {
			compatible = "mediatek,mt8163-disp_ovl1";
			reg = <0x00 0x14008000 0x00 0x1000>;
			interrupts = <0x00 0xb9 0x08>;
		};

		disp_rdma0@14009000 {
			compatible = "mediatek,mt8163-disp_rdma0";
			reg = <0x00 0x14009000 0x00 0x1000>;
			interrupts = <0x00 0xba 0x08>;
		};

		disp_rdma1@1400a000 {
			compatible = "mediatek,mt8163-disp_rdma1";
			reg = <0x00 0x1400a000 0x00 0x1000>;
			interrupts = <0x00 0xbb 0x08>;
		};

		disp_wdma0@1400b000 {
			compatible = "mediatek,mt8163-disp_wdma0";
			reg = <0x00 0x1400b000 0x00 0x1000>;
			interrupts = <0x00 0xbc 0x08>;
		};

		disp_color@1400c000 {
			compatible = "mediatek,mt8163-disp_color";
			reg = <0x00 0x1400c000 0x00 0x1000>;
			interrupts = <0x00 0xbd 0x08>;
		};

		disp_ccorr@1400d000 {
			compatible = "mediatek,mt8163-disp_ccorr";
			reg = <0x00 0x1400d000 0x00 0x1000>;
			interrupts = <0x00 0xbe 0x08>;
		};

		disp_aal@1400e000 {
			compatible = "mediatek,mt8163-disp_aal";
			reg = <0x00 0x1400e000 0x00 0x1000>;
			interrupts = <0x00 0xbf 0x08>;
		};

		disp_gamma@1400f000 {
			compatible = "mediatek,mt8163-disp_gamma";
			reg = <0x00 0x1400f000 0x00 0x1000>;
			interrupts = <0x00 0xc0 0x08>;
		};

		disp_dither@14010000 {
			compatible = "mediatek,mt8163-disp_dither";
			reg = <0x00 0x14010000 0x00 0x1000>;
			interrupts = <0x00 0xc1 0x08>;
		};

		disp_ufoe@14011000 {
			compatible = "mediatek,mt8163-disp_ufoe";
			reg = <0x00 0x14011000 0x00 0x1000>;
		};

		disp_dsi0@14012000 {
			compatible = "mediatek,mt8163-disp_dsi0";
			reg = <0x00 0x14012000 0x00 0x1000>;
			interrupts = <0x00 0xc3 0x08>;
		};

		disp_dpi0@14013000 {
			compatible = "mediatek,mt8163-disp_dpi0";
			reg = <0x00 0x14013000 0x00 0x1000>;
			interrupts = <0x00 0xc4 0x08>;
		};

		disp_dpi1@1401c000 {
			compatible = "mediatek,mt8163-disp_dpi1";
			reg = <0x00 0x1401c000 0x00 0x1000>;
			interrupts = <0x00 0xc9 0x08>;
		};

		hdmi@1401d000 {
			compatible = "mediatek,mt8163-hdmitx";
			power-domains = <0x2c 0x00>;
			reg = <0x00 0x1401d000 0x00 0x1000 0x00 0x1100f000 0x00 0x10 0x00 0x10013000 0x00 0xbc>;
			interrupts = <0x00 0xca 0x08>;
			clocks = <0x05 0x25 0x05 0x26 0x0e 0x2a 0x0e 0x2d 0x0e 0x2c 0x0e 0x2b>;
			clock-names = "cec_pdn\0clk_cec_26m\0mmsys_hdmi_pll\0mmsys_hdmi_pixel\0mmsys_hdmi_audio\0mmsys_hdmi_spidif";
			pinctrl-names = "default\0hdmi_hpd";
			pinctrl-0 = <0x3d>;
			pinctrl-1 = <0x3e>;
			hdmi_power_control = <0x0d 0x1b 0x00>;
		};

		disp_pwm0@14014000 {
			compatible = "mediatek,mt8163-disp_pwm";
			reg = <0x00 0x14014000 0x00 0x1000>;
		};

		mm_mutex@14015000 {
			compatible = "mediatek,mt8163-disp_mutex";
			reg = <0x00 0x14015000 0x00 0x1000>;
			interrupts = <0x00 0xb1 0x08>;
		};

		disp_wdma1@14018000 {
			compatible = "mediatek,mt8163-disp_wdma1";
			reg = <0x00 0x14018000 0x00 0x1000>;
			interrupts = <0x00 0xc6 0x08>;
		};

		disp_config2@10206000 {
			compatible = "mediatek,mt8163-disp_config2";
			reg = <0x00 0x10206000 0x00 0x1000>;
		};

		disp_config3@10000000 {
			compatible = "mediatek,mt8163-disp_config3";
			reg = <0x00 0x10000000 0x00 0x1000>;
		};

		disp_mipi@10215000 {
			compatible = "mediatek,mt8163-disp_mipi";
			reg = <0x00 0x10215000 0x00 0x1000>;
		};

		disp_io_driving@10005000 {
			compatible = "mediatek,mt8163-disp_io_driving";
			reg = <0x00 0x10005000 0x00 0x1000>;
		};

		disp_tvdpll_cfg6@100000a0 {
			compatible = "mediatek,mt8163-disp_tvdpll_cfg6";
			reg = <0x00 0x100000a0 0x00 0x1000>;
		};

		disp_tvdpll_con0@1000c270 {
			compatible = "mediatek,mt8163-disp_tvdpll_con0";
			reg = <0x00 0x1000c270 0x00 0x1000>;
		};

		disp_tvdpll_con1@1000c274 {
			compatible = "mediatek,mt8163-disp_tvdpll_con1";
			reg = <0x00 0x1000c274 0x00 0x1000>;
		};

		disp_lvds_ana@10215800 {
			compatible = "mediatek,mt8163-disp_lvds_ana";
			reg = <0x00 0x10215800 0x00 0x1000>;
		};

		g3d_iommu@13005000 {
			cell-index = <0x02>;
			compatible = "mediatek,mt8163-g3d_iommu";
			reg = <0x00 0x13005000 0x00 0x1000>;
			interrupts = <0x00 0xe2 0x08>;
		};

		larb@14016000 {
			compatible = "mediatek,mt8163-smi-larb";
			reg = <0x00 0x14016000 0x00 0x1000>;
			interrupts = <0x00 0xcd 0x08>;
			mediatek,smi = <0x3f>;
			mediatek,larbid = <0x00>;
			clocks = <0x0e 0x01 0x0e 0x01>;
			clock-names = "apb\0smi";
			power-domains = <0x2c 0x00>;
		};

		smi@14017000 {
			compatible = "mediatek,mt8163-smi";
			reg = <0x00 0x14017000 0x00 0x1000>;
			clocks = <0x0e 0x00 0x0e 0x00>;
			clock-names = "apb\0smi";
			power-domains = <0x2c 0x00>;
			linux,phandle = <0x3f>;
			phandle = <0x3f>;
		};

		met_smi@14017000 {
			compatible = "mediatek,met_smi";
			reg = <0x00 0x14017000 0x00 0x1000 0x00 0x14016000 0x00 0x1000 0x00 0x16010000 0x00 0x1000 0x00 0x15001000 0x00 0x1000 0x00 0x17001000 0x00 0x1000>;
			clocks = <0x0e 0x00 0x0e 0x01 0x40 0x00 0x41 0x00 0x42 0x01>;
			clock-names = "smi-common\0smi-larb0\0vdec-larb1\0img-larb2\0venc-larb3";
		};

		disp_lvds_tx@1401b200 {
			compatible = "mediatek,mt8163-disp_lvds_tx";
			reg = <0x00 0x1401b200 0x00 0x1000>;
		};

		imgsys@15000000 {
			compatible = "mediatek,mt8163-imgsys\0syscon";
			reg = <0x00 0x15000000 0x00 0x1000>;
			#clock-cells = <0x01>;
			linux,phandle = <0x41>;
			phandle = <0x41>;
		};

		isp_display {
			compatible = "mediatek,mt8163-isp_display";
		};

		ispsys@15000000 {
			compatible = "mediatek,mt8163-ispsys";
			reg = <0x00 0x15004000 0x00 0x9000 0x00 0x15000000 0x00 0x10000 0x00 0x10217000 0x00 0x3000>;
			interrupts = <0x00 0xda 0x08 0x00 0xdb 0x08>;
			clocks = <0x41 0x00 0x41 0x02 0x41 0x03 0x41 0x04 0x41 0x05 0x41 0x06 0x0e 0x00>;
			clock-names = "IMG_LARB2_SMI\0IMG_CAM_SMI\0IMG_CAM_CAM\0IMG_SEN_TG\0IMG_SEN_CAM\0IMG_CAM_SV\0MM_SMI_COMMON";
		};

		larb@15001000 {
			compatible = "mediatek,mt8163-smi-larb";
			reg = <0x00 0x15001000 0x00 0x1000>;
			interrupts = <0x00 0xd9 0x08>;
			mediatek,smi = <0x3f>;
			mediatek,larbid = <0x02>;
			clocks = <0x41 0x00 0x41 0x00>;
			clock-names = "apb\0smi";
			power-domains = <0x2c 0x03>;
		};

		camera1@15008000 {
			compatible = "mediatek,mt8163-camera_hw";
			reg = <0x00 0x15008000 0x00 0x1000>;
			clocks = <0x06 0x47 0x06 0x36 0x06 0x39>;
			clock-names = "TOP_CAMTG_SEL\0TOP_UNIVPLL_D26\0TOP_UNIVPLL2_D2";
			reg-vcama-supply = <0x43>;
			reg-vcamd-supply = <0x44>;
			reg-vcamio-supply = <0x45>;
			reg-vcamaf-supply = <0x46>;
			pinctrl-names = "default\0cam0_rst0\0cam0_rst1\0cam0_pnd0\0cam0_pnd1\0cam1_rst0\0cam1_rst1\0cam1_pnd0\0cam1_pnd1\0cam_mclk0\0cam_mclk1";
			pinctrl-0 = <0x47>;
			pinctrl-1 = <0x48>;
			pinctrl-2 = <0x49>;
			pinctrl-3 = <0x4a>;
			pinctrl-4 = <0x4b>;
			pinctrl-5 = <0x4c>;
			pinctrl-6 = <0x4d>;
			pinctrl-7 = <0x4e>;
			pinctrl-8 = <0x4f>;
			pinctrl-9 = <0x50>;
			pinctrl-10 = <0x51>;
			status = "okay";
		};

		camera2@15008000 {
			compatible = "mediatek,mt8163-camera_hw2";
			reg = <0x00 0x15008000 0x00 0x1000>;
			reg-vcama-supply = <0x43>;
			reg-vcamd-supply = <0x44>;
			reg-vcamio-supply = <0x45>;
			reg-vcamaf-supply = <0x46>;
		};

		vdecsys@16000000 {
			compatible = "mediatek,mt8163-vdecsys\0syscon";
			reg = <0x00 0x16000000 0x00 0x1000>;
			#clock-cells = <0x01>;
			linux,phandle = <0x40>;
			phandle = <0x40>;
		};

		vdec_gcon@16000000 {
			compatible = "mediatek,mt8163-vdec_gcon";
			reg = <0x00 0x16000000 0x00 0x10000>;
		};

		larb@16010000 {
			compatible = "mediatek,mt8163-smi-larb";
			reg = <0x00 0x16010000 0x00 0x10000>;
			interrupts = <0x00 0xd5 0x08>;
			mediatek,smi = <0x3f>;
			mediatek,larbid = <0x01>;
			clocks = <0x40 0x00 0x40 0x01>;
			clock-names = "apb\0smi";
			power-domains = <0x2c 0x01>;
		};

		vdec@16020000 {
			compatible = "mediatek,mt8163-vdec";
			reg = <0x00 0x16020000 0x00 0x10000>;
			interrupts = <0x00 0xd4 0x08>;
		};

		vencsys@17000000 {
			compatible = "mediatek,mt8163-vencsys\0syscon";
			reg = <0x00 0x17000000 0x00 0x1000>;
			#clock-cells = <0x01>;
			linux,phandle = <0x42>;
			phandle = <0x42>;
		};

		larb@17001000 {
			compatible = "mediatek,mt8163-smi-larb";
			reg = <0x00 0x17001000 0x00 0x1000>;
			interrupts = <0x00 0xcf 0x08>;
			mediatek,smi = <0x3f>;
			mediatek,larbid = <0x03>;
			clocks = <0x42 0x01 0x42 0x00>;
			clock-names = "apb\0smi";
			power-domains = <0x2c 0x02>;
		};

		venc@17002000 {
			compatible = "mediatek,mt8163-venc";
			reg = <0x00 0x17002000 0x00 0x1000>;
			interrupts = <0x00 0xce 0x08>;
		};

		jpgenc@17003000 {
			compatible = "mediatek,mt8163-jpgenc\0mediatek,jpgenc";
			reg = <0x00 0x17003000 0x00 0x1000>;
			interrupts = <0x00 0xd0 0x08>;
			clocks = <0x42 0x02>;
			clock-names = "venc-jpgenc";
		};

		btcvsd@18000000 {
			compatible = "mediatek,mt8163-audio_bt_cvsd\0mediatek,audio_bt_cvsd";
			offset = <0xf00 0x800 0xfd0 0xfd4 0xfd8>;
			reg = <0x00 0x10001000 0x00 0x1000 0x00 0x18000000 0x00 0x10000 0x00 0x18080000 0x00 0x8000>;
			interrupts = <0x00 0xec 0x08>;
		};

		consys@18070000 {
			compatible = "mediatek,mt8163-consys";
			reg = <0x00 0x18070000 0x00 0x200 0x00 0x10001000 0x00 0x1000>;
			power-domains = <0x2c 0x04>;
			interrupts = <0x00 0xed 0x08 0x00 0xec 0x08>;
			resets = <0x52 0x0c>;
			reset-names = "connsys";
			status = "okay";
			pinctrl-names = "default\0gps_lna_state_init\0gps_lna_state_oh\0gps_lna_state_ol";
			pinctrl-0 = <0x53>;
			pinctrl-1 = <0x54>;
			pinctrl-2 = <0x55>;
			pinctrl-3 = <0x56>;
			vcn18-supply = <0x57>;
			vcn28-supply = <0x58>;
			vcn33_bt-supply = <0x59>;
			vcn33_wifi-supply = <0x5a>;
		};

		wifi@180f0000 {
			compatible = "mediatek,wifi";
			reg = <0x00 0x180f0000 0x00 0x5c>;
			interrupts = <0x00 0xee 0x08>;
			clocks = <0x05 0x29>;
			clock-names = "wifi-dma";
		};

		accdet@ {
			compatible = "mediatek,mt8163-accdet";
			status = "okay";
			interrupt-parent = <0x0d>;
			interrupts = <0x04 0x08>;
			eint-debounce = <0x100>;
			accdet-gpio = <0x0d 0x1a 0x00>;
			hpswitch-gpio = <0x0d 0x57 0x00>;
			accdet-mic-vol = <0x07>;
			headset-mode-setting = <0x900 0x900 0x01 0x3f0 0x800 0x800 0x20>;
			accdet-plugout-debounce = <0x14>;
			accdet-mic-mode = <0x01>;
			headset-three-key-threshold = <0x00 0x50 0xdc 0x1f4>;
			headset-four-key-threshold = <0x00 0x3a 0x79 0xc0 0x1c2>;
			pinctrl-names = "default\0state_eint_as_int";
			pinctrl-0 = <0x5b>;
			pinctrl-1 = <0x5c>;
		};

		touch@ {
			compatible = "mediatek,mt8163-touch";
			vtouch-supply = <0x26>;
			tpd-resolution = <0x320 0x500>;
			use-tpd-button = <0x00>;
			tpd-key-num = <0x04>;
			tpd-key-local = <0x8b 0xac 0x9e 0x00>;
			tpd-key-dim-local = <0x3c 0x352 0x32 0x1e 0xb4 0x352 0x32 0x1e 0x12c 0x352 0x32 0x1e 0x1a4 0x352 0x32 0x1e>;
			tpd-max-touch-num = <0x05>;
			tpd-filter-enable = <0x01>;
			tpd-filter-pixel-density = <0x7c>;
			tpd-filter-custom-prameters = <0x00 0x00 0x00 0x00 0x00 0x00 0x00 0x00 0x00 0x00 0x00 0x00>;
			tpd-filter-custom-speed = <0x00 0x00 0x00>;
			pinctrl-names = "default\0state_eint_as_int\0state_eint_output0\0state_eint_output1\0state_rst_output0\0state_rst_output1";
			pinctrl-0 = <0x5d>;
			pinctrl-1 = <0x5e>;
			pinctrl-2 = <0x5f>;
			pinctrl-3 = <0x60>;
			pinctrl-4 = <0x61>;
			pinctrl-5 = <0x62>;
			status = "okay";
		};

		gps {
			compatible = "mediatek,gps";
		};

		hwmsensor@0 {
			compatible = "mediatek,hwmsensor";
		};

		gsensor@0 {
			compatible = "mediatek,gsensor";
		};

		als_ps@0 {
			compatible = "mediatek,als_ps";
		};

		batchsensor@0 {
			compatible = "mediatek,batchsensor";
		};

		gyroscope@0 {
			compatible = "mediatek,gyroscope";
		};

		barometer@0 {
			compatible = "mediatek,barometer";
		};

		msensor@0 {
			compatible = "mediatek,msensor";
		};

		orientation@0 {
			compatible = "mediatek,orientation";
		};

		shf {
			compatible = "mediatek,shf";
		};

		step_counter@0 {
			compatible = "mediatek,step_counter";
		};

		shake@0 {
			compatible = "mediatek,shake";
		};

		m_shk_pl@0 {
			compatible = "mediatek,m_shk_pl";
		};

		face_down@0 {
			compatible = "mediatek,face_down";
		};

		m_fdn_pl@0 {
			compatible = "mediatek,m_fdn_pl";
		};

		led@0 {
			compatible = "mediatek,red";
			led_mode = <0x03>;
			data = <0x06>;
			pwm_config = <0x00 0x00 0x00 0x00 0x00>;
		};

		led@1 {
			compatible = "mediatek,green";
			led_mode = <0x03>;
			data = <0x07>;
			pwm_config = <0x00 0x00 0x00 0x00 0x00>;
		};

		led@2 {
			compatible = "mediatek,blue";
			led_mode = <0x00>;
			data;
			pwm_config = <0x00 0x00 0x00 0x00 0x00>;
		};

		led@3 {
			compatible = "mediatek,jogball-backlight";
			led_mode = <0x00>;
			data;
			pwm_config = <0x00 0x00 0x00 0x00 0x00>;
		};

		led@4 {
			compatible = "mediatek,keyboard-backlight";
			led_mode = <0x00>;
			data;
			pwm_config = <0x00 0x00 0x00 0x00 0x00>;
		};

		led@5 {
			compatible = "mediatek,button-backlight";
			led_mode = <0x00>;
			data;
			pwm_config = <0x00 0x00 0x00 0x00 0x00>;
		};

		led@6 {
			compatible = "mediatek,lcd-backlight";
			led_mode = <0x05>;
			data;
			pwm_config = <0x00 0x00 0x00 0x00 0x00>;
			gpios = <0x0d 0x2b 0x00>;
		};

		mtkfb@0 {
			compatible = "mediatek,MTKFB";
			clocks = <0x0e 0x09 0x0e 0x0a 0x0e 0x0b 0x0e 0x0c 0x0e 0x0d 0x0e 0x0e 0x0e 0x17 0x0e 0x0f 0x0e 0x10 0x0e 0x11 0x0e 0x12 0x0e 0x13 0x0e 0x14 0x0e 0x20 0x0e 0x21 0x0e 0x22 0x0e 0x23 0x0e 0x24 0x0e 0x25 0x0e 0x26 0x0e 0x27 0x0e 0x28 0x0e 0x29 0x0e 0x2e 0x0e 0x2f 0x06 0x55 0x28 0x0a 0x06 0x14 0x06 0x15 0x06 0x16 0x06 0x59 0x28 0x06 0x06 0x2d 0x06 0x2e 0x06 0x2f 0x06 0x30 0x06 0x44>;
			clock-names = "MMSYS_CLK_FAKE_ENG\0MMSYS_CLK_DISP_OVL0\0MMSYS_CLK_DISP_OVL1\0MMSYS_CLK_DISP_RDMA0\0MMSYS_CLK_DISP_RDMA1\0MMSYS_CLK_DISP_WDMA0\0MMSYS_CLK_DISP_WDMA1\0MMSYS_CLK_DISP_COLOR\0MMSYS_CLK_DISP_CCORR\0MMSYS_CLK_DISP_AAL\0MMSYS_CLK_DISP_GAMMA\0MMSYS_CLK_DISP_DITHER\0MMSYS_CLK_DISP_UFOE\0MMSYS_CLK_DISP_PWM\0MMSYS_CLK_DISP_PWM26M\0MMSYS_CLK_DSI_ENGINE\0MMSYS_CLK_DSI_DIGITAL\0MMSYS_CLK_DPI0_PIXEL\0MMSYS_CLK_DPI0_ENGINE\0MMSYS_CLK_LVDS_PIXEL\0MMSYS_CLK_LVDS_CTS\0MMSYS_CLK_DPI1_PIXEL\0MMSYS_CLK_DPI1_ENGINE\0MMSYS_CLK_DISP_DSC_ENGINE\0MMSYS_CLK_DISP_DSC_MEM\0MMSYS_CLK_MUX_DPI0_SEL\0MMSYS_APMIXED_LVDSPLL\0MMSYS_CLK_MUX_LVDSPLL_D2\0MMSYS_CLK_MUX_LVDSPLL_D4\0MMSYS_CLK_MUX_LVDSPLL_D8\0MMSYS_CLK_MUX_DPI1_SEL\0MMSYS_APMIXED_TVDPLL\0MMSYS_CLK_MUX_TVDPLL_D2\0MMSYS_CLK_MUX_TVDPLL_D4\0MMSYS_CLK_MUX_TVDPLL_D8\0MMSYS_CLK_MUX_TVDPLL_D16\0MMSYS_CLK_PWM_SEL";
		};

		bat_meter {
			compatible = "mediatek,bat_meter";
			r_bat_sense = <0x04>;
			r_i_sense = <0x04>;
			r_charger_1 = <0x14a>;
			r_charger_2 = <0x27>;
			temperature_t0 = <0x6e>;
			temperature_t1 = <0x00>;
			temperature_t2 = <0x19>;
			temperature_t3 = <0x32>;
			temperature_t = <0xff>;
			fg_meter_resistance = <0x00>;
			q_max_pos_50 = <0x12f1>;
			q_max_pos_25 = <0x1328>;
			q_max_pos_0 = <0x1358>;
			q_max_neg_10 = <0x135b>;
			q_max_pos_50_h_current = <0x12cf>;
			q_max_pos_25_h_current = <0x1303>;
			q_max_pos_0_h_current = <0x112c>;
			q_max_neg_10_h_current = <0xc34>;
			oam_d5 = <0x00>;
			change_tracking_point = <0x01>;
			cust_tracking_point = <0x0e>;
			cust_r_sense = <0xc8>;
			cust_hw_cc = <0x00>;
			aging_tuning_value = <0x64>;
			cust_r_fg_offset = <0x00>;
			ocv_board_compesate = <0x00>;
			r_fg_board_base = <0x3e8>;
			r_fg_board_slope = <0x3e8>;
			car_tune_value = <0x59>;
			current_detect_r_fg = <0x0a>;
			minerroroffset = <0x3e8>;
			fg_vbat_average_size = <0x12>;
			r_fg_value = <0x0a>;
			cust_poweron_delta_capacity_tolrance = <0x50>;
			cust_poweron_low_capacity_tolrance = <0x02>;
			cust_poweron_max_vbat_tolrance = <0x46>;
			cust_poweron_delta_vbat_tolrance = <0x3c>;
			cust_poweron_delta_hw_sw_ocv_capacity_tolrance = <0x0a>;
			fixed_tbat_25 = <0x00>;
			vbat_normal_wakeup = <0xe10>;
			vbat_low_power_wakeup = <0xdac>;
			normal_wakeup_period = <0x1518>;
			low_power_wakeup_period = <0x12c>;
			close_poweroff_wakeup_period = <0x1e>;
			rbat_pull_up_r = <0x4204>;
			rbat_pull_up_volt = <0x708>;
			batt_temperature_table_num = <0x11>;
			batt_temperature_table = <0xffffffec 0x1250e 0xfffffff1 0xe246 0xfffffff6 0xb070 0xfffffffb 0x8adc 0x00 0x6e40 0x05 0x5843 0x0a 0x4737 0x0f 0x39e4 0x14 0x2f65 0x19 0x2710 0x1e 0x2067 0x23 0x1b0a 0x28 0x16b2 0x2d 0x1327 0x32 0x1040 0x37 0xddb 0x3c 0xbdf>;
			battery_profile_t0_num = <0x5f>;
			battery_profile_t0 = <0x00 0x1128 0x01 0x1110 0x02 0x10fd 0x03 0x10ec 0x04 0x10dd 0x05 0x10ce 0x07 0x10c0 0x08 0x10b1 0x09 0x10a5 0x0a 0x1097 0x0b 0x108a 0x0c 0x107d 0x0d 0x1070 0x0e 0x1064 0x0f 0x1057 0x10 0x104b 0x11 0x103f 0x13 0x1033 0x14 0x1026 0x15 0x101a 0x16 0x100e 0x17 0x1003 0x18 0xff9 0x19 0xfef 0x1a 0xfe3 0x1b 0xfd6 0x1c 0xfc4 0x1d 0xfb2 0x1f 0xfa0 0x20 0xf90 0x21 0xf82 0x22 0xf78 0x23 0xf6e 0x24 0xf66 0x25 0xf5e 0x26 0xf55 0x27 0xf4f 0x28 0xf47 0x29 0xf3f 0x2b 0xf37 0x2c 0xf2e 0x2d 0xf27 0x2e 0xf20 0x2f 0xf19 0x30 0xf12 0x31 0xf0c 0x32 0xf05 0x33 0xeff 0x34 0xef9 0x35 0xef4 0x36 0xeef 0x38 0xeea 0x39 0xee6 0x3a 0xee2 0x3b 0xedd 0x3c 0xed8 0x3d 0xed5 0x3e 0xed2 0x3f 0xed0 0x40 0xecd 0x41 0xecb 0x42 0xec9 0x44 0xec7 0x45 0xec6 0x46 0xec4 0x47 0xec2 0x48 0xebf 0x49 0xebd 0x4a 0xeba 0x4b 0xeb7 0x4c 0xeb4 0x4d 0xeb1 0x4e 0xead 0x50 0xea9 0x51 0xea5 0x52 0xea0 0x53 0xe9b 0x54 0xe95 0x55 0xe8f 0x56 0xe88 0x57 0xe82 0x58 0xe7c 0x59 0xe77 0x5a 0xe74 0x5c 0xe6f 0x5d 0xe6b 0x5e 0xe64 0x5f 0xe57 0x60 0xe40 0x61 0xe18 0x62 0xde3 0x63 0xda9 0x64 0xd6a 0x64 0xd28 0x64 0xce1>;
			battery_profile_t1_num = <0x5f>;
			battery_profile_t1 = <0x00 0x112a 0x01 0x1114 0x02 0x1104 0x03 0x10f5 0x04 0x10e7 0x05 0x10da 0x07 0x10cb 0x08 0x10be 0x09 0x10b1 0x0a 0x10a4 0x0b 0x1098 0x0c 0x108a 0x0d 0x107e 0x0e 0x1071 0x0f 0x1065 0x10 0x1058 0x11 0x104c 0x13 0x1040 0x14 0x1034 0x15 0x1028 0x16 0x101d 0x17 0x1010 0x18 0x1005 0x19 0xffa 0x1a 0xff1 0x1b 0xfe7 0x1c 0xfdd 0x1d 0xfcf 0x1f 0xfbd 0x20 0xfac 0x21 0xf9c 0x22 0xf90 0x23 0xf86 0x24 0xf7d 0x25 0xf74 0x26 0xf6b 0x27 0xf61 0x28 0xf58 0x29 0xf4f 0x2b 0xf45 0x2c 0xf3b 0x2d 0xf32 0x2e 0xf29 0x2f 0xf21 0x30 0xf1a 0x31 0xf13 0x32 0xf0c 0x33 0xf06 0x34 0xf01 0x35 0xefb 0x37 0xef5 0x38 0xef1 0x39 0xeec 0x3a 0xee8 0x3b 0xee3 0x3c 0xedf 0x3d 0xedb 0x3e 0xed8 0x3f 0xed5 0x40 0xed1 0x41 0xece 0x43 0xecb 0x44 0xec9 0x45 0xec7 0x46 0xec6 0x47 0xec4 0x48 0xec3 0x49 0xec1 0x4a 0xebf 0x4b 0xebc 0x4c 0xeb9 0x4d 0xeb6 0x4f 0xeb3 0x50 0xeb0 0x51 0xeac 0x52 0xea7 0x53 0xea2 0x54 0xe9c 0x55 0xe95 0x56 0xe8e 0x57 0xe86 0x58 0xe7e 0x59 0xe77 0x5b 0xe73 0x5c 0xe6f 0x5d 0xe6b 0x5e 0xe67 0x5f 0xe60 0x60 0xe50 0x61 0xe2a 0x62 0xdee 0x63 0xd97 0x64 0xd2a 0x64 0xca9 0x64 0xc18>;
			battery_profile_t2_num = <0x5f>;
			battery_profile_t2 = <0x00 0x1129 0x01 0x1116 0x02 0x1106 0x03 0x10f7 0x04 0x10ea 0x06 0x10a7 0x07 0x1090 0x08 0x1084 0x09 0x107e 0x0a 0x1068 0x0b 0x1060 0x0c 0x1056 0x0d 0x104d 0x0e 0x1040 0x0f 0x1033 0x11 0x101d 0x12 0x1010 0x13 0x1006 0x14 0xffa 0x15 0xff0 0x16 0xfe6 0x17 0xfdc 0x18 0xfd2 0x19 0xfc8 0x1a 0xfbe 0x1c 0xfa8 0x1d 0xf9e 0x1e 0xf91 0x1f 0xf88 0x20 0xf7e 0x21 0xf75 0x22 0xf6c 0x23 0xf64 0x24 0xf5c 0x25 0xf53 0x27 0xf3f 0x28 0xf37 0x29 0xf2c 0x2a 0xf23 0x2b 0xf1c 0x2c 0xf13 0x2d 0xf0c 0x2e 0xf05 0x2f 0xf00 0x30 0xefa 0x32 0xeef 0x33 0xeea 0x34 0xee5 0x35 0xee0 0x36 0xedc 0x37 0xed8 0x38 0xed3 0x39 0xecc 0x3a 0xecb 0x3b 0xec5 0x3d 0xebf 0x3e 0xebc 0x3f 0xeb9 0x40 0xeb6 0x41 0xeb2 0x42 0xeae 0x43 0xeac 0x44 0xeaa 0x45 0xea6 0x46 0xea2 0x48 0xe9c 0x49 0xe9a 0x4a 0xe8d 0x4b 0xe8a 0x4c 0xe87 0x4d 0xe85 0x4e 0xe84 0x4f 0xe82 0x50 0xe80 0x51 0xe7e 0x53 0xe7c 0x54 0xe77 0x55 0xe71 0x56 0xe6c 0x57 0xe65 0x58 0xe60 0x59 0xe57 0x5a 0xe54 0x5b 0xe51 0x5c 0xe4f 0x5e 0xe49 0x5f 0xe47 0x60 0xe42 0x61 0xe3a 0x62 0xe36 0x63 0xe10 0x64 0xd33 0x64 0xc27 0x64 0xbf9 0x64 0xbd4>;
			battery_profile_t3_num = <0x5f>;
			battery_profile_t3 = <0x00 0x1122 0x01 0x1103 0x02 0x10f4 0x03 0x10e6 0x04 0x10d9 0x06 0x10cb 0x07 0x10be 0x08 0x10b1 0x09 0x10a4 0x0a 0x1097 0x0b 0x108a 0x0c 0x107d 0x0d 0x1070 0x0e 0x1063 0x10 0x1057 0x11 0x104a 0x12 0x103d 0x13 0x1031 0x14 0x1025 0x15 0x1018 0x16 0x100c 0x17 0x1001 0x18 0xff5 0x1a 0xfea 0x1b 0xfdf 0x1c 0xfd3 0x1d 0xfc9 0x1e 0xfbe 0x1f 0xfb4 0x20 0xfa9 0x21 0xfa0 0x23 0xf96 0x24 0xf8d 0x25 0xf84 0x26 0xf7b 0x27 0xf73 0x28 0xf6a 0x29 0xf61 0x2a 0xf58 0x2b 0xf4d 0x2d 0xf3c 0x2e 0xf2d 0x2f 0xf24 0x30 0xf1c 0x31 0xf14 0x32 0xf0e 0x33 0xf07 0x34 0xf01 0x35 0xefc 0x37 0xef7 0x38 0xef2 0x39 0xeed 0x3a 0xee8 0x3b 0xee4 0x3c 0xee0 0x3d 0xedb 0x3e 0xed8 0x3f 0xed5 0x41 0xed1 0x42 0xece 0x43 0xecb 0x44 0xec7 0x45 0xec4 0x46 0xec1 0x47 0xebe 0x48 0xeb6 0x49 0xead 0x4b 0xea7 0x4c 0xea2 0x4d 0xe9e 0x4e 0xe98 0x4f 0xe94 0x50 0xe90 0x51 0xe8d 0x52 0xe88 0x54 0xe83 0x55 0xe7c 0x56 0xe76 0x57 0xe70 0x58 0xe68 0x59 0xe5f 0x5a 0xe5c 0x5b 0xe5c 0x5c 0xe5a 0x5e 0xe59 0x5f 0xe56 0x60 0xe4b 0x61 0xe24 0x62 0xded 0x63 0xda2 0x64 0xd31 0x64 0xc40 0x64 0xbd2 0x64 0xbd2 0x64 0xbd2>;
			r_profile_t0_num = <0x5f>;
			r_profile_t0 = <0x2e7 0x1128 0x2e7 0x1110 0x2e6 0x10fd 0x2e1 0x10ec 0x2dd 0x10dd 0x2d9 0x10ce 0x2cf 0x10c0 0x2c9 0x10b1 0x2c6 0x10a5 0x2bf 0x1097 0x2b8 0x108a 0x2b4 0x107d 0x2ad 0x1070 0x2a9 0x1064 0x2a4 0x1057 0x2a0 0x104b 0x29d 0x103f 0x299 0x1033 0x293 0x1026 0x28e 0x101a 0x28c 0x100e 0x289 0x1003 0x288 0xff9 0x287 0xfef 0x288 0xfe3 0x285 0xfd6 0x279 0xfc4 0x271 0xfb2 0x267 0xfa0 0x261 0xf90 0x25b 0xf82 0x259 0xf78 0x25b 0xf6e 0x25b 0xf66 0x258 0xf5e 0x257 0xf55 0x257 0xf4f 0x256 0xf47 0x256 0xf3f 0x256 0xf37 0x255 0xf2e 0x256 0xf27 0x257 0xf20 0x259 0xf19 0x259 0xf12 0x25a 0xf0c 0x25c 0xf05 0x261 0xeff 0x264 0xef9 0x267 0xef4 0x269 0xeef 0x26c 0xeea 0x271 0xee6 0x275 0xee2 0x277 0xedd 0x27b 0xed8 0x280 0xed5 0x286 0xed2 0x28d 0xed0 0x294 0xecd 0x29d 0xecb 0x2a4 0xec9 0x2ac 0xec7 0x2b6 0xec6 0x2c1 0xec4 0x2ca 0xec2 0x2d6 0xebf 0x2e3 0xebd 0x2f1 0xeba 0x300 0xeb7 0x30f 0xeb4 0x324 0xeb1 0x339 0xead 0x34b 0xea9 0x364 0xea5 0x37e 0xea0 0x399 0xe9b 0x3b5 0xe95 0x3d3 0xe8f 0x3ef 0xe88 0x40f 0xe82 0x42d 0xe7c 0x448 0xe77 0x467 0xe74 0x487 0xe6f 0x4aa 0xe6b 0x4d2 0xe64 0x503 0xe57 0x543 0xe40 0x550 0xe18 0x4aa 0xde3 0x403 0xda9 0x39a 0xd6a 0x32c 0xd28 0x2b6 0xce1>;
			r_profile_t1_num = <0x5f>;
			r_profile_t1 = <0x17b 0x112a 0x17b 0x1114 0x178 0x1104 0x175 0x10f5 0x172 0x10e7 0x16e 0x10da 0x16a 0x10cb 0x167 0x10be 0x162 0x10b1 0x15f 0x10a4 0x15f 0x1098 0x15b 0x108a 0x15a 0x107e 0x159 0x1071 0x157 0x1065 0x154 0x1058 0x155 0x104c 0x155 0x1040 0x153 0x1034 0x153 0x1028 0x153 0x101d 0x151 0x1010 0x152 0x1005 0x151 0xffa 0x155 0xff1 0x159 0xfe7 0x15c 0xfdd 0x15c 0xfcf 0x154 0xfbd 0x14e 0xfac 0x14a 0xf9c 0x148 0xf90 0x147 0xf86 0x147 0xf7d 0x145 0xf74 0x13f 0xf6b 0x13b 0xf61 0x139 0xf58 0x138 0xf4f 0x135 0xf45 0x132 0xf3b 0x130 0xf32 0x12f 0xf29 0x12f 0xf21 0x12f 0xf1a 0x12f 0xf13 0x130 0xf0c 0x130 0xf06 0x131 0xf01 0x134 0xefb 0x134 0xef5 0x137 0xef1 0x138 0xeec 0x139 0xee8 0x13c 0xee3 0x13c 0xedf 0x140 0xedb 0x142 0xed8 0x145 0xed5 0x147 0xed1 0x149 0xece 0x14b 0xecb 0x14e 0xec9 0x151 0xec7 0x157 0xec6 0x159 0xec4 0x15d 0xec3 0x163 0xec1 0x167 0xebf 0x16c 0xebc 0x171 0xeb9 0x176 0xeb6 0x17e 0xeb3 0x187 0xeb0 0x18f 0xeac 0x198 0xea7 0x1a5 0xea2 0x1b1 0xe9c 0x1bd 0xe95 0x1cd 0xe8e 0x1e0 0xe86 0x1f5 0xe7e 0x20d 0xe77 0x22e 0xe73 0x256 0xe6f 0x288 0xe6b 0x2cb 0xe67 0x323 0xe60 0x392 0xe50 0x3f8 0xe2a 0x44e 0xdee 0x462 0xd97 0x3bf 0xd2a 0x2e8 0xca9 0x1f6 0xc18>;
			r_profile_t2_num = <0x5f>;
			r_profile_t2 = <0x80 0x1129 0x80 0x1116 0x80 0x1106 0x7e 0x10f7 0x7e 0x10ea 0x80 0x10dd 0x7f 0x10ce 0x7e 0x10c1 0x7e 0x10b4 0x7e 0x10a7 0x7f 0x109a 0x7e 0x108c 0x80 0x1080 0x80 0x1073 0x80 0x1066 0x7f 0x1059 0x80 0x104c 0x81 0x1040 0x81 0x1033 0x82 0x1028 0x83 0x101b 0x82 0x100f 0x83 0x1003 0x85 0xff8 0x86 0xfed 0x88 0xfe4 0x8a 0xfd9 0x8b 0xfcd 0x8c 0xfc0 0x8c 0xfb4 0x90 0xfa9 0x8e 0xf9f 0x8f 0xf95 0x90 0xf8c 0x91 0xf83 0x93 0xf7d 0x94 0xf74 0x97 0xf6b 0x95 0xf61 0x91 0xf55 0x8b 0xf48 0x84 0xf3b 0x80 0xf2f 0x7d 0xf25 0x7d 0xf1e 0x7b 0xf16 0x7a 0xf0f 0x7a 0xf09 0x79 0xf03 0x7a 0xefe 0x7a 0xef9 0x7b 0xef4 0x7c 0xef0 0x7b 0xeeb 0x7c 0xee7 0x7e 0xee3 0x7e 0xee0 0x80 0xedd 0x7f 0xed8 0x80 0xed5 0x80 0xed2 0x7f 0xecf 0x81 0xecc 0x81 0xeca 0x81 0xec7 0x81 0xec4 0x7f 0xec0 0x7e 0xebc 0x7e 0xeb9 0x7c 0xeb4 0x7b 0xeb0 0x7b 0xeac 0x7c 0xea8 0x7d 0xea4 0x7e 0xea1 0x7e 0xe9d 0x7c 0xe96 0x7c 0xe90 0x7d 0xe89 0x7e 0xe83 0x7e 0xe7b 0x7b 0xe71 0x7a 0xe6e 0x7b 0xe6d 0x7d 0xe6c 0x81 0xe6a 0x84 0xe68 0x86 0xe5c 0x81 0xe36 0x84 0xdfd 0x8c 0xdad 0x99 0xd33 0x00 0xc27 0x00 0xbf9 0x00 0xbd4>;
			r_profile_t3_num = <0x5f>;
			r_profile_t3 = <0x68 0x1122 0x68 0x1103 0x68 0x10f4 0x66 0x10e6 0x68 0x10d9 0x67 0x10cb 0x66 0x10be 0x66 0x10b1 0x68 0x10a4 0x67 0x1097 0x67 0x108a 0x6a 0x107d 0x68 0x1070 0x68 0x1063 0x6a 0x1057 0x6a 0x104a 0x69 0x103d 0x69 0x1031 0x69 0x1025 0x69 0x1018 0x69 0x100c 0x6a 0x1001 0x6c 0xff5 0x6b 0xfea 0x6b 0xfdf 0x6c 0xfd3 0x6e 0xfc9 0x6d 0xfbe 0x6e 0xfb4 0x6f 0xfa9 0x70 0xfa0 0x6f 0xf96 0x71 0xf8d 0x72 0xf84 0x73 0xf7b 0x74 0xf73 0x76 0xf6a 0x78 0xf61 0x79 0xf58 0x78 0xf4d 0x70 0xf3c 0x6a 0xf2d 0x6a 0xf24 0x6a 0xf1c 0x68 0xf14 0x68 0xf0e 0x68 0xf07 0x68 0xf01 0x68 0xefc 0x6a 0xef7 0x69 0xef2 0x69 0xeed 0x69 0xee8 0x6b 0xee4 0x6b 0xee0 0x6b 0xedb 0x6c 0xed8 0x6d 0xed5 0x6e 0xed1 0x6f 0xece 0x6f 0xecb 0x6f 0xec7 0x6f 0xec4 0x6f 0xec1 0x6f 0xebe 0x6b 0xeb6 0x69 0xead 0x6b 0xea7 0x6a 0xea2 0x6b 0xe9e 0x69 0xe98 0x6a 0xe94 0x68 0xe90 0x69 0xe8d 0x6a 0xe88 0x6c 0xe83 0x6b 0xe7c 0x6b 0xe76 0x6c 0xe70 0x6a 0xe68 0x69 0xe5f 0x69 0xe5c 0x69 0xe5c 0x6e 0xe5a 0x71 0xe59 0x75 0xe56 0x75 0xe4b 0x6f 0xe24 0x70 0xded 0x73 0xda2 0x7c 0xd31 0xdf 0xc40 0x29 0xbd2 0x29 0xbd2 0x29 0xbd2>;
		};

		bat_meter1 {
			compatible = "mediatek,bat_meter1";
			r_bat_sense = <0x04>;
			r_i_sense = <0x04>;
			r_charger_1 = <0x14a>;
			r_charger_2 = <0x27>;
			temperature_t0 = <0x6e>;
			temperature_t1 = <0x00>;
			temperature_t2 = <0x19>;
			temperature_t3 = <0x32>;
			temperature_t = <0xff>;
			fg_meter_resistance = <0x00>;
			q_max_pos_50 = <0x133b>;
			q_max_pos_25 = <0x1378>;
			q_max_pos_0 = <0x133b>;
			q_max_neg_10 = <0x12c6>;
			q_max_pos_50_h_current = <0x1316>;
			q_max_pos_25_h_current = <0x1346>;
			q_max_pos_0_h_current = <0x1105>;
			q_max_neg_10_h_current = <0x8f0>;
			oam_d5 = <0x00>;
			change_tracking_point = <0x01>;
			cust_tracking_point = <0x0e>;
			cust_r_sense = <0xc8>;
			cust_hw_cc = <0x00>;
			aging_tuning_value = <0x64>;
			cust_r_fg_offset = <0x00>;
			ocv_board_compesate = <0x00>;
			r_fg_board_base = <0x3e8>;
			r_fg_board_slope = <0x3e8>;
			car_tune_value = <0x59>;
			current_detect_r_fg = <0x0a>;
			minerroroffset = <0x3e8>;
			fg_vbat_average_size = <0x12>;
			r_fg_value = <0x0a>;
			cust_poweron_delta_capacity_tolrance = <0x50>;
			cust_poweron_low_capacity_tolrance = <0x02>;
			cust_poweron_max_vbat_tolrance = <0x46>;
			cust_poweron_delta_vbat_tolrance = <0x3c>;
			cust_poweron_delta_hw_sw_ocv_capacity_tolrance = <0x0a>;
			fixed_tbat_25 = <0x00>;
			vbat_normal_wakeup = <0xe10>;
			vbat_low_power_wakeup = <0xdac>;
			normal_wakeup_period = <0x1518>;
			low_power_wakeup_period = <0x12c>;
			close_poweroff_wakeup_period = <0x1e>;
			rbat_pull_up_r = <0x4204>;
			rbat_pull_up_volt = <0x708>;
			batt_temperature_table_num = <0x11>;
			batt_temperature_table = <0xffffffec 0x1250e 0xfffffff1 0xe246 0xfffffff6 0xb070 0xfffffffb 0x8adc 0x00 0x6e40 0x05 0x5843 0x0a 0x4737 0x0f 0x39e4 0x14 0x2f65 0x19 0x2710 0x1e 0x2067 0x23 0x1b0a 0x28 0x16b2 0x2d 0x1327 0x32 0x1040 0x37 0xddb 0x3c 0xbdf>;
			battery_profile_t0_num = <0x5f>;
			battery_profile_t0 = <0x00 0x111e 0x01 0x1102 0x02 0x10ed 0x03 0x10db 0x04 0x10cb 0x06 0x10bd 0x07 0x10ae 0x08 0x10a0 0x09 0x1092 0x0a 0x1085 0x0b 0x1078 0x0c 0x106b 0x0d 0x105f 0x0f 0x1053 0x10 0x1047 0x11 0x103b 0x12 0x102f 0x13 0x1023 0x14 0x1017 0x15 0x100c 0x16 0x1001 0x18 0xff8 0x19 0xfee 0x1a 0xfe2 0x1b 0xfd4 0x1c 0xfc2 0x1d 0xfb0 0x1e 0xf9f 0x1f 0xf8f 0x21 0xf82 0x22 0xf78 0x23 0xf6e 0x24 0xf66 0x25 0xf5f 0x26 0xf57 0x27 0xf50 0x28 0xf48 0x2a 0xf41 0x2b 0xf39 0x2c 0xf31 0x2d 0xf2a 0x2e 0xf22 0x2f 0xf1b 0x30 0xf15 0x31 0xf0e 0x33 0xf08 0x34 0xf02 0x35 0xefd 0x36 0xef8 0x37 0xef2 0x38 0xeee 0x39 0xee9 0x3a 0xee5 0x3c 0xee0 0x3d 0xedd 0x3e 0xed9 0x3f 0xed6 0x40 0xed3 0x41 0xed0 0x42 0xece 0x43 0xecc 0x45 0xec9 0x46 0xec7 0x47 0xec5 0x48 0xec3 0x49 0xec1 0x4a 0xebf 0x4b 0xebc 0x4c 0xeba 0x4e 0xeb7 0x4f 0xeb4 0x50 0xeb2 0x51 0xeae 0x52 0xeab 0x53 0xea7 0x54 0xea2 0x55 0xe9e 0x57 0xe98 0x58 0xe93 0x59 0xe8d 0x5a 0xe87 0x5b 0xe82 0x5c 0xe7d 0x5d 0xe79 0x5e 0xe75 0x60 0xe70 0x61 0xe6a 0x62 0xe61 0x63 0xe10 0x64 0xd3d 0x64 0xd3d 0x64 0xd1e 0x64 0xd0c 0x64 0xd0c 0x64 0xd0c>;
			battery_profile_t1_num = <0x5f>;
			battery_profile_t1 = <0x00 0x111d 0x01 0x1105 0x02 0x10f2 0x03 0x10e2 0x04 0x10d3 0x05 0x10c5 0x07 0x10b7 0x08 0x10aa 0x09 0x109d 0x0a 0x1090 0x0b 0x1083 0x0c 0x1077 0x0d 0x106a 0x0e 0x105f 0x0f 0x1053 0x10 0x1047 0x12 0x103b 0x13 0x102f 0x14 0x1023 0x15 0x1018 0x16 0x100c 0x17 0x1001 0x18 0xff8 0x19 0xff0 0x1a 0xfe8 0x1b 0xfdc 0x1d 0xfcb 0x1e 0xfb7 0x1f 0xfa6 0x20 0xf98 0x21 0xf8d 0x22 0xf84 0x23 0xf7c 0x24 0xf75 0x25 0xf6e 0x26 0xf66 0x28 0xf5d 0x29 0xf53 0x2a 0xf49 0x2b 0xf3f 0x2c 0xf36 0x2d 0xf2c 0x2e 0xf24 0x2f 0xf1c 0x30 0xf15 0x31 0xf0e 0x33 0xf08 0x34 0xf02 0x35 0xefd 0x36 0xef7 0x37 0xef2 0x38 0xeee 0x39 0xee9 0x3a 0xee5 0x3b 0xee2 0x3c 0xede 0x3e 0xeda 0x3f 0xed7 0x40 0xed4 0x41 0xed1 0x42 0xece 0x43 0xecc 0x44 0xeca 0x45 0xec9 0x46 0xec7 0x47 0xec5 0x49 0xec4 0x4a 0xec2 0x4b 0xec0 0x4c 0xebe 0x4d 0xebb 0x4e 0xeb9 0x4f 0xeb6 0x50 0xeb2 0x51 0xeaf 0x52 0xeaa 0x54 0xea5 0x55 0xea0 0x56 0xe9a 0x57 0xe94 0x58 0xe8d 0x59 0xe85 0x5a 0xe7d 0x5b 0xe78 0x5c 0xe73 0x5d 0xe70 0x5f 0xe6d 0x60 0xe68 0x61 0xe5e 0x62 0xe45 0x63 0xe18 0x64 0xd3d 0x64 0xd3d 0x64 0xd3d 0x64 0xd3d>;
			battery_profile_t2_num = <0x5f>;
			battery_profile_t2 = <0x00 0x111b 0x01 0x1104 0x02 0x10f2 0x03 0x10e2 0x04 0x10d3 0x05 0x10c5 0x07 0x10b8 0x08 0x10aa 0x09 0x109d 0x0a 0x1090 0x0b 0x1083 0x0c 0x1077 0x0d 0x106a 0x0e 0x105e 0x0f 0x1051 0x10 0x1045 0x12 0x1039 0x13 0x102d 0x14 0x1021 0x15 0x1014 0x16 0x1009 0x17 0xffe 0x18 0xff2 0x19 0xfe8 0x1a 0xfe1 0x1b 0xfd8 0x1d 0xfc9 0x1e 0xfb7 0x1f 0xfa9 0x20 0xf9d 0x21 0xf94 0x22 0xf8e 0x23 0xf88 0x24 0xf81 0x25 0xf79 0x26 0xf70 0x28 0xf68 0x29 0xf5f 0x2a 0xf55 0x2b 0xf4a 0x2c 0xf3e 0x2d 0xf32 0x2e 0xf26 0x2f 0xf1c 0x30 0xf14 0x31 0xf0d 0x32 0xf06 0x34 0xf01 0x35 0xefc 0x36 0xef6 0x37 0xef1 0x38 0xeed 0x39 0xee8 0x3a 0xee4 0x3b 0xee0 0x3c 0xedd 0x3d 0xed9 0x3f 0xed5 0x40 0xed3 0x41 0xed0 0x42 0xecd 0x43 0xecb 0x44 0xec7 0x45 0xec4 0x46 0xec3 0x47 0xebf 0x48 0xebd 0x4a 0xeb9 0x4b 0xeb6 0x4c 0xeb3 0x4d 0xeaf 0x4e 0xeab 0x4f 0xea7 0x50 0xea3 0x51 0xea0 0x52 0xe9b 0x53 0xe96 0x54 0xe90 0x56 0xe89 0x57 0xe83 0x58 0xe7c 0x59 0xe73 0x5a 0xe6d 0x5b 0xe6b 0x5c 0xe6a 0x5d 0xe69 0x5e 0xe66 0x5f 0xe5f 0x61 0xe41 0x62 0xe0c 0x63 0xdc2 0x64 0xd33 0x64 0xcce 0x64 0xcce 0x64 0xc24>;
			battery_profile_t3_num = <0x5f>;
			battery_profile_t3 = <0x00 0x110e 0x01 0x10f7 0x02 0x10e4 0x03 0x10d3 0x04 0x10c4 0x05 0x10b6 0x07 0x10a8 0x08 0x109a 0x09 0x108d 0x0a 0x1081 0x0b 0x1074 0x0c 0x1068 0x0d 0x105b 0x0e 0x104e 0x0f 0x1042 0x10 0x1036 0x12 0x102a 0x13 0x101e 0x14 0x1012 0x15 0x1006 0x16 0xffb 0x17 0xff0 0x18 0xfe5 0x19 0xfda 0x1a 0xfcf 0x1b 0xfc4 0x1d 0xfba 0x1e 0xfb1 0x1f 0xfa7 0x20 0xf9d 0x21 0xf93 0x22 0xf8a 0x23 0xf81 0x24 0xf79 0x25 0xf71 0x26 0xf69 0x27 0xf61 0x29 0xf59 0x2a 0xf51 0x2b 0xf48 0x2c 0xf3e 0x2d 0xf2f 0x2e 0xf21 0x2f 0xf16 0x30 0xf0f 0x31 0xf08 0x32 0xf02 0x34 0xefc 0x35 0xef7 0x36 0xef2 0x37 0xeed 0x38 0xee8 0x39 0xee5 0x3a 0xee0 0x3b 0xedc 0x3c 0xed8 0x3d 0xed5 0x3f 0xed1 0x40 0xece 0x41 0xecb 0x42 0xec8 0x43 0xec6 0x44 0xec4 0x45 0xec1 0x46 0xebe 0x47 0xebb 0x48 0xeb6 0x49 0xead 0x4b 0xea6 0x4c 0xea2 0x4d 0xe9e 0x4e 0xe9a 0x4f 0xe95 0x50 0xe91 0x51 0xe8d 0x52 0xe8a 0x53 0xe85 0x54 0xe80 0x56 0xe78 0x57 0xe73 0x58 0xe6c 0x59 0xe63 0x5a 0xe5d 0x5b 0xe5c 0x5c 0xe5a 0x5d 0xe59 0x5e 0xe57 0x5f 0xe51 0x61 0xe36 0x62 0xe05 0x63 0xdc2 0x64 0xd3d 0x64 0xcc2 0x64 0xcc2 0x64 0xcc2>;
			r_profile_t0_num = <0x5f>;
			r_profile_t0 = <0x3c3 0x111e 0x3c3 0x1102 0x409 0x10ed 0x3c2 0x10db 0x39d 0x10cb 0x42e 0x10bd 0x3e3 0x10ae 0x3d6 0x10a0 0x3cd 0x1092 0x3c5 0x1085 0x3b8 0x1078 0x3a9 0x106b 0x3a4 0x105f 0x39b 0x1053 0x391 0x1047 0x382 0x103b 0x37f 0x102f 0x355 0x1023 0x369 0x1017 0x368 0x100c 0x363 0x1001 0x35a 0xff8 0x354 0xfee 0x352 0xfe2 0x34d 0xfd4 0x33b 0xfc2 0x331 0xfb0 0x32c 0xf9f 0x325 0xf8f 0x31b 0xf82 0x318 0xf78 0x319 0xf6e 0x318 0xf66 0x318 0xf5f 0x316 0xf57 0x313 0xf50 0x30e 0xf48 0x30e 0xf41 0x30a 0xf39 0x30a 0xf31 0x30c 0xf2a 0x307 0xf22 0x304 0xf1b 0x30c 0xf15 0x309 0xf0e 0x307 0xf08 0x30f 0xf02 0x309 0xefd 0x314 0xef8 0x30c 0xef2 0x318 0xeee 0x311 0xee9 0x31d 0xee5 0x319 0xee0 0x322 0xedd 0x322 0xed9 0x322 0xed6 0x331 0xed3 0x32d 0xed0 0x331 0xece 0x33b 0xecc 0x336 0xec9 0x345 0xec7 0x34d 0xec5 0x34a 0xec3 0x35a 0xec1 0x369 0xebf 0x372 0xebc 0x377 0xeba 0x378 0xeb7 0x382 0xeb4 0x38c 0xeb2 0x398 0xeae 0x3a2 0xeab 0x3af 0xea7 0x3bd 0xea2 0x3cc 0xe9e 0x3d7 0xe98 0x3f0 0xe93 0x3f7 0xe8d 0x412 0xe87 0x42c 0xe82 0x43f 0xe7d 0x46d 0xe79 0x48b 0xe75 0x4b3 0xe70 0x4ec 0xe6a 0x512 0xe61 0x555 0xe51 0x593 0xe37 0x593 0xe37 0x593 0xe37 0x593 0xe37 0x593 0xe37 0x593 0xe37>;
			r_profile_t1_num = <0x5f>;
			r_profile_t1 = <0x1fb 0x111d 0x1fb 0x1105 0x1f7 0x10f2 0x1f4 0x10e2 0x1ef 0x10d3 0x1ec 0x10c5 0x1e5 0x10b7 0x1de 0x10aa 0x1d8 0x109d 0x1d1 0x1090 0x1ce 0x1083 0x1ca 0x1077 0x1c7 0x106a 0x1c4 0x105f 0x1c0 0x1053 0x1bb 0x1047 0x1b6 0x103b 0x1b3 0x102f 0x1ae 0x1023 0x1b0 0x1018 0x1ac 0x100c 0x1a9 0x1001 0x1a9 0xff8 0x1a9 0xff0 0x1ab 0xfe8 0x1a7 0xfdc 0x19f 0xfcb 0x197 0xfb7 0x192 0xfa6 0x192 0xf98 0x190 0xf8d 0x192 0xf84 0x192 0xf7c 0x192 0xf75 0x190 0xf6e 0x18b 0xf66 0x189 0xf5d 0x184 0xf53 0x181 0xf49 0x17f 0xf3f 0x17e 0xf36 0x179 0xf2c 0x179 0xf24 0x177 0xf1c 0x177 0xf15 0x179 0xf0e 0x17a 0xf08 0x17a 0xf02 0x17e 0xefd 0x17f 0xef7 0x17f 0xef2 0x183 0xeee 0x183 0xee9 0x188 0xee5 0x18d 0xee2 0x18e 0xede 0x192 0xeda 0x195 0xed7 0x198 0xed4 0x19a 0xed1 0x19d 0xece 0x1a1 0xecc 0x1a4 0xeca 0x1a9 0xec9 0x1ae 0xec7 0x1b0 0xec5 0x1b6 0xec4 0x1b6 0xec2 0x1ba 0xec0 0x1bd 0xebe 0x1c2 0xebb 0x1ca 0xeb9 0x1cf 0xeb6 0x1d4 0xeb2 0x1dd 0xeaf 0x1e0 0xeaa 0x1e7 0xea5 0x1ef 0xea0 0x1f6 0xe9a 0x203 0xe94 0x210 0xe8d 0x21c 0xe85 0x229 0xe7d 0x23d 0xe78 0x255 0xe73 0x271 0xe70 0x297 0xe6d 0x2cb 0xe68 0x30a 0xe5e 0x354 0xe45 0x3b3 0xe18 0x43f 0xdd4 0x43f 0xdd4 0x43f 0xdd4 0x43f 0xdd4>;
			r_profile_t2_num = <0x5c>;
			r_profile_t2 = <0xa5 0x1104 0xa5 0x10f2 0xa5 0x10e2 0xa3 0x10d3 0xa2 0x10c5 0xa3 0x10b8 0xa2 0x10aa 0xa2 0x109d 0xa2 0x1090 0xa2 0x1083 0xa5 0x1077 0xa5 0x106a 0xa7 0x105e 0xa5 0x1051 0xa5 0x1045 0xa5 0x1039 0xa5 0x102d 0xa3 0x1021 0xa3 0x1014 0xa3 0x1009 0xa5 0xffe 0xa3 0xff2 0xa3 0xfe8 0xa8 0xfe1 0xaa 0xfd8 0xa7 0xfc9 0xa0 0xfb7 0xa3 0xfa9 0xa7 0xf9d 0xaa 0xf94 0xaa 0xf8e 0xac 0xf88 0xad 0xf81 0xad 0xf79 0xac 0xf70 0xaf 0xf68 0xb1 0xf5f 0xaf 0xf55 0xac 0xf4a 0xa7 0xf3e 0xa2 0xf96 0x9d 0xf26 0x98 0xf1c 0x98 0xf14 0x98 0xf0d 0x96 0xf06 0x98 0xf01 0x98 0xefc 0x98 0xef6 0x98 0xef1 0x99 0xeed 0x9b 0xee8 0x9b 0xee4 0x9b 0xee0 0x9d 0xedd 0x9d 0xed9 0x99 0xf39 0x9b 0xed3 0x9e 0xed0 0x9e 0xecd 0xa0 0xecb 0xa0 0xec7 0xa0 0xec4 0xa0 0xec3 0x9d 0xebf 0x9e 0xebd 0x9e 0xeb9 0x9d 0xeb6 0x9d 0xeb3 0x9e 0xeaf 0xa0 0xeab 0xa0 0xea7 0xa0 0xea3 0xa3 0xea0 0xa2 0xe9b 0xa2 0xe96 0xa5 0xe90 0xa5 0xe89 0xa7 0xe83 0xa8 0xe7c 0xaa 0xed7 0xa8 0xe6d 0xac 0xe6b 0xb1 0xe6a 0xb7 0xe69 0xbe 0xe66 0xc1 0xe5f 0xbc 0xe41 0xc5 0xe70 0xd5 0xdc2 0xee 0xd53 0x174 0xc6a>;
			r_profile_t3_num = <0x5f>;
			r_profile_t3 = <0x70 0x110e 0x70 0x10f7 0x6e 0x10e4 0x6e 0x10d3 0x6e 0x10c4 0x70 0x10b6 0x6e 0x10a8 0x6c 0x109a 0x6e 0x108d 0x70 0x1081 0x6e 0x1074 0x70 0x1068 0x70 0x105b 0x6e 0x104e 0x70 0x1042 0x70 0x1036 0x70 0x102a 0x71 0x101e 0x70 0x1012 0x70 0x1006 0x71 0xffb 0x71 0xff0 0x73 0xfe5 0x73 0xfda 0x73 0xfcf 0x71 0xfc4 0x73 0xfba 0x75 0xfb1 0x75 0xfa7 0x75 0xf9d 0x75 0xf93 0x76 0xf8a 0x75 0xf81 0x78 0xf79 0x7a 0xf71 0x7b 0xf69 0x7d 0xf61 0x7d 0xf59 0x80 0xf51 0x80 0xf48 0x7f 0xf3e 0x7a 0xf2f 0x73 0xf21 0x70 0xf16 0x70 0xf0f 0x6e 0xf08 0x70 0xf02 0x6e 0xefc 0x6e 0xef7 0x70 0xef2 0x70 0xeed 0x6e 0xee8 0x71 0xee5 0x70 0xee0 0x70 0xedc 0x71 0xed8 0x71 0xed5 0x71 0xed1 0x73 0xece 0x73 0xecb 0x73 0xec8 0x75 0xec6 0x76 0xec4 0x76 0xec1 0x76 0xebe 0x76 0xebb 0x75 0xeb6 0x71 0xead 0x70 0xea6 0x71 0xea2 0x71 0xe9e 0x73 0xe9a 0x71 0xe95 0x71 0xe91 0x71 0xe8d 0x73 0xe8a 0x73 0xe85 0x75 0xe80 0x71 0xe78 0x75 0xe73 0x73 0xe6c 0x73 0xe63 0x70 0xe5d 0x73 0xe5c 0x71 0xe5a 0x76 0xe59 0x7b 0xe57 0x7f 0xe51 0x78 0xe36 0x7a 0xe05 0x7b 0xdc2 0x85 0xd64 0xa0 0xcc2 0xa0 0xcc2 0xa0 0xcc2>;
		};

		BAT_NOTIFY {
			compatible = "mediatek,bat_notify";
		};

		bat_comm {
			compatible = "mediatek,battery";
			stop_charging_in_takling = <0x01>;
			talking_recharge_voltage = <0xed8>;
			talking_sync_time = <0x3c>;
			mtk_temperature_recharge_support = <0x01>;
			max_charge_temperature = <0x32>;
			max_charge_temperature_minus_x_degree = <0x2f>;
			min_charge_temperature = <0x00>;
			min_charge_temperature_plus_x_degree = <0x06>;
			err_charge_temperature = <0xff>;
			v_pre2cc_thres = <0xd48>;
			v_cc2topoff_thres = <0xfd2>;
			recharging_voltage = <0x100e>;
			charging_full_current = <0x64>;
			config_usb_if = <0x00>;
			usb_charger_current_suspend = <0x00>;
			usb_charger_current_unconfigured = <0x1b58>;
			usb_charger_current_configured = <0xc350>;
			usb_charger_current = <0xc350>;
			ac_charger_current = <0x186a0>;
			non_std_ac_charger_current = <0xc350>;
			charging_host_charger_current = <0xfde8>;
			apple_0_5a_charger_current = <0xc350>;
			apple_1_0a_charger_current = <0xfde8>;
			apple_2_1a_charger_current = <0x13880>;
			bat_low_temp_protect_enable = <0x00>;
			v_charger_enable = <0x00>;
			v_charger_max = <0x1964>;
			v_charger_min = <0x1130>;
			onehundred_percent_tracking_time = <0x0a>;
			npercent_tracking_time = <0x14>;
			sync_to_real_tracking_time = <0x3c>;
			v_0percent_tracking = <0xd7a>;
			high_battery_voltage_support = <0x01>;
		};

		dumchar {
			compatible = "mediatek,mt8163-dummy_char";
		};

		ice_debug {
			compatible = "mediatek,mt8163-ice_debug\0mediatek,mt8173-ice_debug";
			clocks = <0x05 0x2f>;
			clock-names = "ice_dbg";
		};

		isp_pipemgr {
			compatible = "mediatek,mt8163-isp_pipemgr";
		};

		isp_sysram {
			compatible = "mediatek,mt8163-isp_sysram";
		};

		mtee {
			compatible = "mediatek,mtee";
			clocks = <0x05 0x20>;
			clock-names = "GCPU";
		};
	};

	lcm {
		compatible = "mediatek,lcm";
		lcm_enp_gpio = <0x0d 0x31 0x00>;
		lcm_enn_gpio = <0x0d 0x32 0x00>;
		lcm_reset_gpio = <0x0d 0x30 0x00>;
		reg-lcm-supply = <0x63>;
	};

	memory@00000000 {
		device_type = "memory";
		reg = <0x00 0x40000000 0x00 0x20000000>;
	};

	chosen {
		bootargs = "console=ttyS0,921600n1 root=/dev/ram initrd=0x44000200,0x200000";
	};

	cust_accel@0 {
		compatible = "mediatek,mc34xx";
		i2c_num = <0x02>;
		i2c_addr = <0x4c 0x00 0x00 0x00>;
		direction = <0x05>;
		power_id = <0xffff>;
		power_vol = <0x00>;
		firlen = <0x00>;
		is_batch_supported = <0x00>;
	};

	cust_accel@1 {
		compatible = "mediatek,kxtj2_1009";
		i2c_num = <0x02>;
		i2c_addr = <0x0e 0x00 0x00 0x00>;
		direction = <0x05>;
		power_id = <0xffff>;
		power_vol = <0x00>;
		firlen = <0x00>;
		is_batch_supported = <0x00>;
	};

	cust_gyro@0 {
		compatible = "mediatek,mpu6050gy";
		i2c_num = <0x02>;
		i2c_addr = <0x68 0x00 0x00 0x00>;
		direction = <0x07>;
		power_id = <0xffff>;
		power_vol = <0x00>;
		firlen = <0x00>;
		is_batch_supported = <0x00>;
	};

	cust_mag@0 {
		compatible = "mediatek,akm09911";
		i2c_num = <0x02>;
		i2c_addr = <0x0c 0x00 0x00 0x00>;
		direction = <0x06>;
		power_id = <0xffff>;
		power_vol = <0x00>;
		is_batch_supported = <0x00>;
	};

	mtcpufreq {
		compatible = "mediatek,mt8163-cpufreq";
		reg-ext-vproc-supply = <0x64>;
	};

	panel@0 {
		compatible = "lcm,lcm_dts";
		pinctrl-names = "default";
		lcm_enp_gpio = <0x0d 0x31 0x00>;
		lcm_enn_gpio = <0x0d 0x32 0x00>;
		lcm_reset_gpio = <0x0d 0x30 0x00>;
		reg-lcm-supply = <0x63>;
		status = "okay";
	};

	panel@1 {
		compatible = "lcm,lcm_dts_kd";
		pinctrl-names = "default";
		lcm_enp_gpio = <0x0d 0x31 0x00>;
		lcm_enn_gpio = <0x0d 0x32 0x00>;
		lcm_reset_gpio = <0x0d 0x30 0x00>;
		reg-lcm-supply = <0x63>;
		status = "okay";
	};

	panel@2 {
		compatible = "lcm,lcm_dts_txd";
		pinctrl-names = "default";
		lcm_enp_gpio = <0x0d 0x31 0x00>;
		lcm_enn_gpio = <0x0d 0x32 0x00>;
		lcm_reset_gpio = <0x0d 0x30 0x00>;
		reg-lcm-supply = <0x63>;
		status = "okay";
	};

	vibrator@0 {
		compatible = "mediatek,vibrator";
		vib_timer = <0x19>;
		vib_limit = <0x09>;
		vib_vol = <0x05>;
	};
};
